VERSION ""

NS_ :

BS_:

BU_: Gateway EPS IBC RBU RWS PDCR

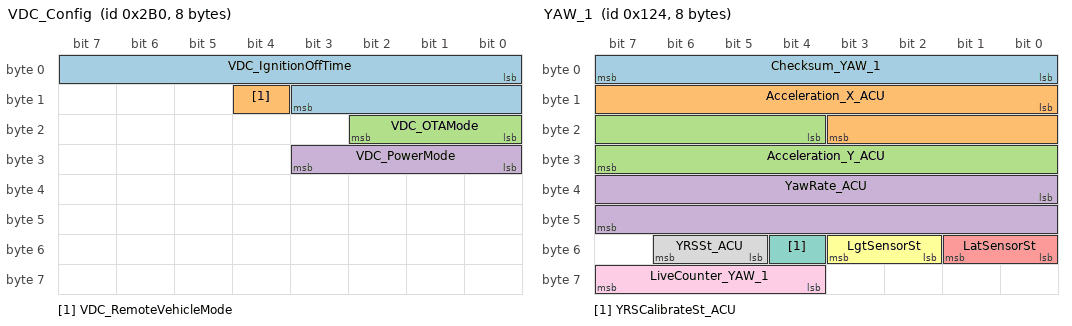
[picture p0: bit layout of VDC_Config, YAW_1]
BO_ 688 VDC_Config: 8 Gateway
 SG_ VDC_IgnitionOffTime : 0|12@1+ (1,0) [0|4095] "minute"  IBC
 SG_ VDC_RemoteVehicleMode : 12|1@1+ (1,0) [0|1] ""  EPS,IBC
 SG_ VDC_OTAMode : 16|3@1+ (1,0) [0|7] ""  EPS
 SG_ VDC_PowerMode : 24|4@1+ (1,0) [0|15] "" Vector__XXX

BO_ 292 YAW_1: 8 Gateway
 SG_ Checksum_YAW_1 : 0|8@1+ (1,0) [0|255] ""  EPS,IBC
 SG_ Acceleration_X_ACU : 8|12@1+ (0.001,-2) [-2|2] "g"  EPS,IBC
 SG_ Acceleration_Y_ACU : 20|12@1+ (0.001,-2) [-2|2] "g"  EPS,IBC
 SG_ YawRate_ACU : 32|16@1+ (0.01,-180) [-180|180] "deg/s"  EPS,IBC
 SG_ LatSensorSt : 48|2@1+ (1,0) [0|3] ""  EPS,IBC
 SG_ LgtSensorSt : 50|2@1+ (1,0) [0|3] ""  EPS,IBC
 SG_ YRSCalibrateSt_ACU : 52|1@1+ (1,0) [0|1] ""  EPS,IBC
 SG_ YRSSt_ACU : 53|2@1+ (1,0) [0|3] ""  EPS,IBC
 SG_ LiveCounter_YAW_1 : 60|4@1+ (1,0) [0|15] ""  EPS,IBC

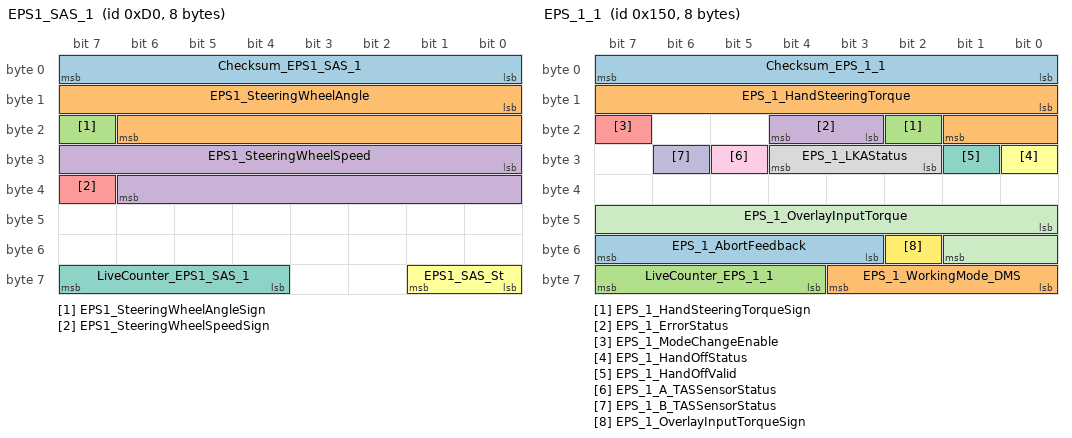
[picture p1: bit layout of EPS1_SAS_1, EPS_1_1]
BO_ 208 EPS1_SAS_1: 8 EPS
 SG_ Checksum_EPS1_SAS_1 : 0|8@1+ (1,0) [0|255] ""  Gateway
 SG_ EPS1_SteeringWheelAngle : 8|15@1+ (0.04375,0) [0|1433.55625] "°„"  Gateway
 SG_ EPS1_SteeringWheelAngleSign : 23|1@1+ (1,0) [0|1] ""  Gateway
 SG_ EPS1_SteeringWheelSpeed : 24|15@1+ (0.04375,0) [0|1433.55625] "°„/s"  Gateway
 SG_ EPS1_SteeringWheelSpeedSign : 39|1@1+ (1,0) [0|1] ""  Gateway
 SG_ EPS1_SAS_St : 56|2@1+ (1,0) [0|3] ""  Gateway
 SG_ LiveCounter_EPS1_SAS_1 : 60|4@1+ (1,0) [0|15] ""  Gateway

BO_ 336 EPS_1_1: 8 EPS
 SG_ Checksum_EPS_1_1 : 0|8@1+ (1,0) [0|255] ""  Gateway
 SG_ EPS_1_HandSteeringTorque : 8|10@1+ (0.01,0) [0|10] "Nm"  Gateway
 SG_ EPS_1_HandSteeringTorqueSign : 18|1@1+ (1,0) [0|1] ""  Gateway
 SG_ EPS_1_ErrorStatus : 19|2@1+ (1,0) [0|3] ""  Gateway
 SG_ EPS_1_ModeChangeEnable : 23|1@1+ (1,0) [0|1] ""  Gateway
 SG_ EPS_1_HandOffStatus : 24|1@1+ (1,0) [0|1] ""  Gateway
 SG_ EPS_1_HandOffValid : 25|1@1+ (1,0) [0|1] ""  Gateway
 SG_ EPS_1_LKAStatus : 26|3@1+ (1,0) [0|7] ""  Gateway
 SG_ EPS_1_A_TASSensorStatus : 29|1@1+ (1,0) [0|1] ""  Gateway
 SG_ EPS_1_B_TASSensorStatus : 30|1@1+ (1,0) [0|1] ""  Gateway
 SG_ EPS_1_OverlayInputTorque : 40|10@1+ (0.01,0) [0|10] "Nm"  Gateway
 SG_ EPS_1_OverlayInputTorqueSign : 50|1@1+ (1,0) [0|1] ""  Gateway
 SG_ EPS_1_AbortFeedback : 51|5@1+ (1,0) [0|31] ""  Gateway
 SG_ EPS_1_WorkingMode_DMS : 56|4@1+ (1,0) [0|15] ""  Gateway
 SG_ LiveCounter_EPS_1_1 : 60|4@1+ (1,0) [0|15] "Pulse"  Gateway

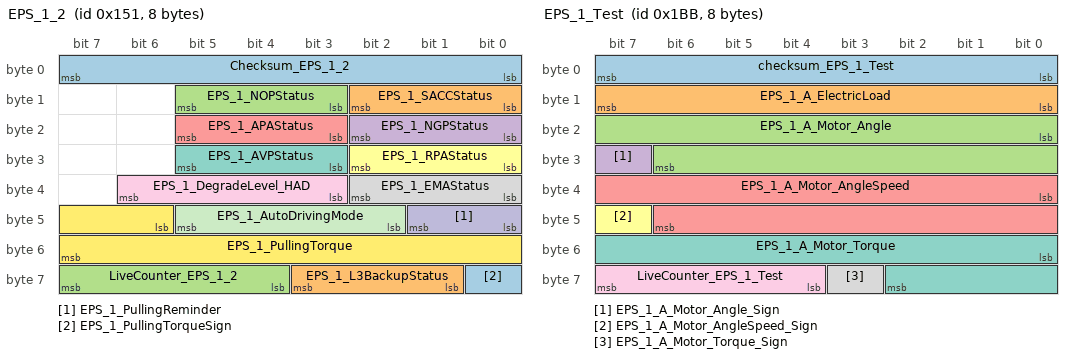
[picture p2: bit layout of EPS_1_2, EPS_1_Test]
BO_ 337 EPS_1_2: 8 EPS
 SG_ Checksum_EPS_1_2 : 0|8@1+ (1,0) [0|255] ""  Gateway
 SG_ EPS_1_SACCStatus : 8|3@1+ (1,0) [0|7] ""  Gateway
 SG_ EPS_1_NOPStatus : 11|3@1+ (1,0) [0|7] ""  Gateway
 SG_ EPS_1_NGPStatus : 16|3@1+ (1,0) [0|7] ""  Gateway
 SG_ EPS_1_APAStatus : 19|3@1+ (1,0) [0|7] ""  Gateway
 SG_ EPS_1_RPAStatus : 24|3@1+ (1,0) [0|7] ""  Gateway
 SG_ EPS_1_AVPStatus : 27|3@1+ (1,0) [0|7] ""  Gateway
 SG_ EPS_1_EMAStatus : 32|3@1+ (1,0) [0|7] ""  Gateway
 SG_ EPS_1_DegradeLevel_HAD : 35|4@1+ (1,0) [0|15] ""  Gateway
 SG_ EPS_1_PullingReminder : 40|2@1+ (1,0) [0|3] ""  Gateway
 SG_ EPS_1_AutoDrivingMode : 42|4@1+ (1,0) [0|15] ""  Gateway
 SG_ EPS_1_PullingTorque : 46|10@1+ (0.01,0) [0|10] "Nm"  Gateway
 SG_ EPS_1_PullingTorqueSign : 56|1@1+ (1,0) [0|1] ""  Gateway
 SG_ EPS_1_L3BackupStatus : 57|3@1+ (1,0) [0|7] ""  Gateway
 SG_ LiveCounter_EPS_1_2 : 60|4@1+ (1,0) [0|15] ""  Gateway

BO_ 443 EPS_1_Test: 8 EPS
 SG_ checksum_EPS_1_Test : 0|8@1+ (1,0) [0|255] ""  Gateway
 SG_ EPS_1_A_ElectricLoad : 8|8@1+ (0.5,0) [0|125] "A"  Gateway
 SG_ EPS_1_A_Motor_Angle : 16|15@1+ (0.04375,0) [0|1433.55625] "°„"  Gateway
 SG_ EPS_1_A_Motor_Angle_Sign : 31|1@1+ (1,0) [0|1] ""  Gateway
 SG_ EPS_1_A_Motor_AngleSpeed : 32|15@1+ (0.04375,0) [0|1433.55625] "rad/s"  Gateway
 SG_ EPS_1_A_Motor_AngleSpeed_Sign : 47|1@1+ (1,0) [0|1] ""  Gateway
 SG_ EPS_1_A_Motor_Torque : 48|11@1+ (0.01,0) [0|20] "Nm"  Gateway
 SG_ EPS_1_A_Motor_Torque_Sign : 59|1@1+ (1,0) [0|1] ""  Gateway
 SG_ LiveCounter_EPS_1_Test : 60|4@1+ (1,0) [0|15] "pulse"  Gateway

BO_ 1210 OTA_VersionEPS: 8 EPS
 SG_ SoftwareNumber_EPS : 0|24@1+ (1,0) [0|0] ""  Gateway
 SG_ HardwareRelated_ConfigID_EPS : 24|16@1+ (1,0) [0|0] ""  Gateway

BO_ 192 ABS_1: 32 IBC
 SG_ Checksum_ABS_1 : 0|8@1+ (1,0) [0|255] ""  Gateway
 SG_ WheelSpeed_FL : 8|15@1+ (0.01,0) [0|327.67] "km/h"  Gateway
 SG_ WheelSpeed_FR : 24|15@1+ (0.01,0) [0|327.67] "km/h"  Gateway
 SG_ WheelSpeed_RL : 40|15@1+ (0.01,0) [0|327.67] "km/h"  Gateway
 SG_ WheelSpeed_RR : 56|15@1+ (0.01,0) [0|327.67] "km/h"  Gateway
 SG_ WheelPulse_FL : 72|8@1+ (1,0) [0|255] ""  Gateway
 SG_ WheelPulse_FR : 80|8@1+ (1,0) [0|255] ""  Gateway
 SG_ WheelPulse_RL : 88|8@1+ (1,0) [0|255] ""  Gateway
 SG_ WheelPulse_RR : 96|8@1+ (1,0) [0|255] ""  Gateway
 SG_ WheelSpeedDirection_FL : 104|2@1+ (1,0) [0|3] ""  Gateway
 SG_ WheelSpeedDirection_FR : 106|2@1+ (1,0) [0|3] ""  Gateway
 SG_ WheelSpeedDirection_RL : 108|2@1+ (1,0) [0|3] ""  Gateway
 SG_ WheelSpeedDirection_RR : 110|2@1+ (1,0) [0|3] ""  Gateway
 SG_ WheelSpeedDirection_FL_Q : 112|1@1+ (1,0) [0|1] ""  Gateway
 SG_ WheelSpeedDirection_FR_Q : 113|1@1+ (1,0) [0|1] ""  Gateway
 SG_ WheelSpeedDirection_RL_Q : 114|1@1+ (1,0) [0|1] ""  Gateway
 SG_ WheelSpeedDirection_RR_Q : 115|1@1+ (1,0) [0|1] ""  Gateway
 SG_ VehicleSpeed : 120|15@1+ (0.01,0) [0|327.67] "km/h"  Gateway
 SG_ VehiclSpeed_Q : 135|1@1+ (1,0) [0|1] ""  Gateway
 SG_ DrivingDirection : 136|2@1+ (1,0) [0|3] ""  Gateway
 SG_ DrivingDirection_Q : 138|1@1+ (1,0) [0|1] ""  Gateway
 SG_ BrakeTorqueOnWheels : 152|12@1+ (2,0) [0|8190] "Nm"  Gateway
 SG_ EstimatedWheelPressure_FL : 168|14@1+ (0.03125,-50) [-50|450] "bar"  Gateway
 SG_ EstimatedWheelPressure_FR : 184|14@1+ (0.03125,-50) [-50|450] "bar"  Gateway
 SG_ EstimatedWheelPressure_RL : 200|14@1+ (0.03125,-50) [-50|450] "bar"  Gateway
 SG_ EstimatedWheelPressure_RR : 216|14@1+ (0.03125,-50) [-50|450] "bar"  Gateway
 SG_ LiveCounter_ABS_1 : 252|4@1+ (1,0) [0|15] ""  Gateway

BO_ 195 ESC_1_W: 32 IBC
 SG_ Checksum_ESC_1_W : 0|8@1+ (1,0) [0|255] ""  Gateway
 SG_ TorqueReductionFast_TCS_FrontWhe : 24|13@1+ (1,0) [0|8000] "Nm"  Gateway
 SG_ TorqueIncrease_MSR_FrontWheel : 40|14@1+ (1,-8000) [-8000|8000] "Nm"  Gateway
 SG_ TorqueReductionFast_TCS_RearWhee : 72|13@1+ (1,0) [0|8000] "Nm"  Gateway
 SG_ TorqueIncrease_MSR_RearWheel : 88|14@1+ (1,-8000) [-8000|8000] "Nm"  Gateway
 SG_ ESC_RegenerationTorqueRequest : 104|13@1+ (1,-8000) [-8000|0] "Nm"  Gateway
 SG_ ESC_RegenerationTorqueRequest_Q : 134|2@1+ (1,0) [0|3] ""  Gateway
 SG_ TorqReductionFastSt_TCS_FrontWhe : 138|1@1+ (1,0) [0|1] ""  Gateway
 SG_ TorqueIncreaseSt_MSR_FrontWheel : 140|1@1+ (1,0) [0|1] ""  Gateway
 SG_ TorqReductionFastSt_TCS_RearWhee : 146|1@1+ (1,0) [0|1] ""  Gateway
 SG_ TorqueIncreaseSt_MSR_RearWheel : 148|1@1+ (1,0) [0|1] ""  Gateway
 SG_ ESC_StatusRegenerationTorqueRequ : 150|1@1+ (1,0) [0|1] ""  Gateway
 SG_ ESC_FrontBiasMax : 152|7@1+ (1,0) [0|100] "%"  Gateway
 SG_ ESC_RearBiasMax : 160|7@1+ (1,0) [0|100] "%"  Gateway
 SG_ LiveCounter_ESC_1_W : 252|4@1+ (1,0) [0|15] ""  Gateway

BO_ 306 ESC_2_1: 24 IBC
 SG_ Checksum_ESC_2_1 : 0|8@1+ (1,0) [0|255] ""  Gateway
 SG_ WorkingSt_ESC : 8|1@1+ (1,0) [0|1] ""  Gateway
 SG_ ErrorSt_ESC : 9|1@1+ (1,0) [0|1] ""  Gateway
 SG_ Intervention_ESC : 10|1@1+ (1,0) [0|1] ""  Gateway
 SG_ ErrorSt_ABS : 11|1@1+ (1,0) [0|1] ""  Gateway
 SG_ Intervention_ABS : 12|1@1+ (1,0) [0|1] ""  Gateway
 SG_ ESC_Status_RollerBenchMode : 13|1@1+ (1,0) [0|1] ""  Gateway
 SG_ Intervention_TCS : 14|1@1+ (1,0) [0|1] ""  Gateway
 SG_ ErrorSt_EBD : 15|1@1+ (1,0) [0|1] ""  Gateway
 SG_ AvailableSt_CDP : 16|1@1+ (1,0) [0|1] ""  Gateway
 SG_ Intervention_CDP : 17|1@1+ (1,0) [0|1] ""  Gateway
 SG_ AvailableSt_HHC : 24|1@1+ (1,0) [0|1] ""  Gateway
 SG_ Intervention_HHC : 25|1@1+ (1,0) [0|1] ""  Gateway
 SG_ AvailableSt_HDC : 26|1@1+ (1,0) [0|1] ""  Gateway
 SG_ WorkingSt_HDC : 27|2@1+ (1,0) [0|3] ""  Gateway
 SG_ ErrorSt_AVH : 29|1@1+ (1,0) [0|1] ""  Gateway
 SG_ WorkingSt_AVH : 30|2@1+ (1,0) [0|3] ""  Gateway
 SG_ AvailableSt_AEB : 34|1@1+ (1,0) [0|1] ""  Gateway
 SG_ Intervention_AEB : 35|1@1+ (1,0) [0|1] ""  Gateway
 SG_ AvailableSt_ABP : 36|1@1+ (1,0) [0|1] ""  Gateway
 SG_ Intervention_ABP : 37|1@1+ (1,0) [0|1] ""  Gateway
 SG_ AvailableSt_AWB : 38|1@1+ (1,0) [0|1] ""  Gateway
 SG_ Intervention_AWB : 39|1@1+ (1,0) [0|1] ""  Gateway
 SG_ AvailableSt_HBA : 40|1@1+ (1,0) [0|1] ""  Gateway
 SG_ Intervention_HBA : 41|1@1+ (1,0) [0|1] ""  Gateway
 SG_ Intervention_EmergencyBrake : 45|1@1+ (1,0) [0|1] ""  Gateway
 SG_ VehicleStandstillSt_ESC : 46|1@1+ (1,0) [0|1] ""  Gateway
 SG_ BrakeLightCtrlCmd_ESC : 47|1@1+ (1,0) [0|1] ""  Gateway
 SG_ Intervention_BTCS_F : 50|1@1+ (1,0) [0|1] ""  Gateway
 SG_ Intervention_BTCS_R : 51|1@1+ (1,0) [0|1] ""  Gateway
 SG_ AvailableSt_MSR : 52|1@1+ (1,0) [0|1] ""  Gateway
 SG_ RoughRoadLevel : 57|3@1+ (1,0) [0|7] ""  Gateway
 SG_ BrakeHoldActive : 60|1@1+ (1,0) [0|1] ""  Gateway
 SG_ ParkingRequestToEPB : 62|2@1+ (1,0) [0|3] ""  Gateway
 SG_ WorkingMode_ESC : 64|4@1+ (1,0) [0|15] ""  Gateway
 SG_ ModeChangeEnable_ESC : 69|1@1+ (1,0) [0|1] ""  Gateway
 SG_ WorkingSt_CST : 72|2@1+ (1,0) [0|3] ""  Gateway
 SG_ LiveCounter_ESC_2_1 : 188|4@1+ (1,0) [0|15] ""  Gateway

BO_ 312 ESC_5_1: 24 IBC
 SG_ Checksum_ESC_5_1 : 0|8@1+ (1,0) [0|255] ""  Gateway
 SG_ ESC_TorqueReq_VMC_1 : 8|17@1+ (0.25,-13000) [-13000|13000] "Nm"  Gateway
 SG_ ESC_TorqueReqSt_VMC_1 : 28|2@1+ (1,0) [0|3] ""  Gateway
 SG_ ESC_TargetGearReq_VMC_1 : 32|3@1+ (1,0) [0|7] ""  Gateway
 SG_ ESC_TargetGearReqEnable_VMC_1 : 35|1@1+ (1,0) [0|1] ""  Gateway
 SG_ ESC_SuspendStatus_L2 : 36|3@1+ (1,0) [0|7] ""  Gateway
 SG_ ESC_EPBAvailableSt_L3 : 39|1@1+ (1,0) [0|1] ""  Gateway
 SG_ ESC_CommunicationSt_L3 : 40|1@1+ (1,0) [0|1] ""  Gateway
 SG_ ESC_UsedChannel_L3 : 41|2@1+ (1,0) [0|3] ""  Gateway
 SG_ ESC_ControllerReleaseSt_L3 : 43|1@1+ (1,0) [0|1] ""  Gateway
 SG_ ESC_SuspendStatusByDriver_L3 : 44|2@1+ (1,0) [0|3] ""  Gateway
 SG_ ESC_SuspendStatusByOther_L3 : 46|1@1+ (1,0) [0|1] ""  Gateway
 SG_ ESC_VLC_Error_L12 : 50|2@1+ (1,0) [0|3] ""  Gateway
 SG_ ESC_VLCSt : 52|2@1+ (1,0) [0|3] ""  Gateway
 SG_ ESC_VMC_Error_L3 : 54|3@1+ (1,0) [0|7] ""  Gateway
 SG_ ESC_AutoDriving_LC_Brakemode : 57|2@1+ (1,0) [0|3] ""  Gateway
 SG_ ESC_AutoPark_LC_HPA_Avail : 59|2@1+ (1,0) [0|3] ""  Gateway
 SG_ ESC_AutoPark_LCSt : 72|3@1+ (1,0) [0|7] ""  Gateway
 SG_ ESC_AutoPark_LC_APA_Avail : 76|2@1+ (1,0) [0|3] ""  Gateway
 SG_ ESC_AutoPark_LC_RPA_Avail : 80|2@1+ (1,0) [0|3] ""  Gateway
 SG_ ESC_AutoPark_LC_AVP_Avail : 84|2@1+ (1,0) [0|3] ""  Gateway
 SG_ ESC_AutoPark_LCFailureSt : 88|4@1+ (1,0) [0|15] ""  Gateway
 SG_ ESC_AutoPark_LC_BrakeMode : 92|2@1+ (1,0) [0|3] ""  Gateway
 SG_ ESC_HDCActiveForbidden : 104|1@1+ (1,0) [0|1] ""  Gateway
 SG_ ESC_ESCOffForbidden : 105|1@1+ (1,0) [0|1] ""  Gateway
 SG_ ESC_AVHActiveForbidden : 106|1@1+ (1,0) [0|1] ""  Gateway
 SG_ ESC_ShutOffFinished : 107|1@1+ (1,0) [0|1] ""  Gateway
 SG_ ESC_BrakePadelOverride : 108|1@1+ (1,0) [0|1] ""  Gateway
 SG_ LiveCounter_ESC_5_1 : 188|4@1+ (1,0) [0|15] "Pulse"  Gateway

BO_ 193 IBC_1: 32 IBC
 SG_ Checksum_IBC_1 : 0|8@1+ (1,0) [0|255] ""  Gateway
 SG_ IBC_SimulatorPressure : 8|10@1+ (0.3,-5) [-5|301.9] "bar"  Gateway
 SG_ IBC_SimulatorPressureSt : 18|1@1+ (1,0) [0|1] ""  Gateway
 SG_ IBC_SystemStatus : 19|3@1+ (1,0) [0|7] ""  Gateway
 SG_ IBC_PlungerPressure : 24|10@1+ (0.3,-5) [-5|301.9] "bar"  Gateway
 SG_ IBC_PlungerPressureSt : 34|1@1+ (1,0) [0|1] ""  Gateway
 SG_ IBC_BrakePedalStatus_Q : 38|2@1+ (1,0) [0|3] ""  Gateway
 SG_ IBC_InputRodStroke : 40|10@1+ (0.05,-5) [-5|46.15] "mm"  Gateway
 SG_ IBC_InputRodStrokeSt : 50|1@1+ (1,0) [0|1] ""  Gateway
 SG_ IBC_BrakeFluidWarning : 51|2@1+ (1,0) [0|3] ""  Gateway
 SG_ IBC_BrakePedalStatus : 53|2@1+ (1,0) [0|3] ""  Gateway
 SG_ TwoFootBrakeSt : 57|1@1+ (1,0) [0|1] ""  Gateway
 SG_ DegradedBBFWarning : 58|1@1+ (1,0) [0|1] ""  Gateway
 SG_ IBC_MILInfo : 59|1@1+ (1,0) [0|1] ""  Gateway
 SG_ FWAWarning : 60|2@1+ (1,0) [0|3] ""  Gateway
 SG_ IBC_RearWheelAngleRequest : 64|12@1+ (0.01,-20.48) [-20.48|20.47] "°„"  Gateway
 SG_ IBC_RearWheelAngleRequestSt : 76|1@1+ (1,0) [0|1] ""  Gateway
 SG_ IBC_VDCActive : 77|1@1+ (1,0) [0|1] ""  Gateway
 SG_ LiveCounter_IBC_1 : 252|4@1+ (1,0) [0|15] ""  Gateway

BO_ 513 IBC_Data: 8 IBC
 SG_ IBCdata : 0|64@1+ (1,0) [0|0] ""  Gateway

BO_ 1381 IBC_SlaveFVReq: 8 IBC
 SG_ SECOC_FVReqCode_IBC : 0|8@1+ (1,0) [0|0] ""  Gateway

BO_ 1260 OTA_VersionIBC: 8 IBC
 SG_ SoftwareNumber_IBC : 0|24@1+ (1,0) [0|0] ""  Gateway
 SG_ HardwareRelated_ConfigID_IBC : 24|16@1+ (1,0) [0|0] ""  Gateway

BO_ 1199 OTA_VersionRBU: 8 RBU
 SG_ SoftwareNumber_RBU : 0|24@1+ (1,0) [0|0] ""  Gateway
 SG_ HardwareRelated_ConfigID_RBU : 24|16@1+ (1,0) [0|0] ""  Gateway

BO_ 169 RBU_1: 32 RBU
 SG_ Checksum_RBU_1 : 0|8@1+ (1,0) [0|255] ""  Gateway
 SG_ RBU_WheelSpeed_FL : 8|15@1+ (0.01,0) [0|327.67] "km/h"  Gateway
 SG_ RBU_WheelSpeed_FR : 24|15@1+ (0.01,0) [0|327.67] "km/h"  Gateway
 SG_ RBU_WheelSpeed_RL : 40|15@1+ (0.01,0) [0|327.67] "km/h"  Gateway
 SG_ RBU_WheelSpeed_RR : 56|15@1+ (0.01,0) [0|327.67] "km/h"  Gateway
 SG_ RBU_ErrorSt_SBS : 72|1@1+ (1,0) [0|1] ""  Gateway
 SG_ RBU_Intervention_SBS : 73|1@1+ (1,0) [0|1] ""  Gateway
 SG_ RBU_EPBAvailableSt_L3 : 74|1@1+ (1,0) [0|1] ""  Gateway
 SG_ RBU_UsedChannel_L3 : 75|2@1+ (1,0) [0|3] ""  Gateway
 SG_ RBU_ControllerReleaseSt_L3 : 77|1@1+ (1,0) [0|1] ""  Gateway
 SG_ RBU_SuspendStatusByDriver_L3 : 78|2@1+ (1,0) [0|3] ""  Gateway
 SG_ RBU_BrakePedalStatus_Q : 80|2@1+ (1,0) [0|3] ""  Gateway
 SG_ RBU_BrakePedalStatus : 82|2@1+ (1,0) [0|3] ""  Gateway
 SG_ RBU_VLCSt : 84|2@1+ (1,0) [0|3] ""  Gateway
 SG_ RBU_VMC_Error_L3 : 88|3@1+ (1,0) [0|7] ""  Gateway
 SG_ RBU_DrivingDirection : 91|2@1+ (1,0) [0|3] ""  Gateway
 SG_ RBU_VehicleSpeed : 96|15@1+ (0.01,0) [0|327.67] "km/h"  Gateway
 SG_ RBU_TargetGearReq_VMC_1 : 114|3@1+ (1,0) [0|7] ""  Gateway
 SG_ RBU_TargetGearReqEnable_VMC_1 : 117|1@1+ (1,0) [0|1] ""  Gateway
 SG_ RBU_VehicleStandstillSt : 118|1@1+ (1,0) [0|1] ""  Gateway
 SG_ RBU_BrakeLightCtrlCmd : 119|1@1+ (1,0) [0|1] ""  Gateway
 SG_ LiveCounter_RBU_1 : 252|4@1+ (1,0) [0|15] ""  Gateway

BO_ 1382 RBU_SlaveFVReq: 8 RBU
 SG_ SECOC_FVReqCode_RBU : 0|8@1+ (1,0) [0|0] ""  Gateway

BO_ 1214 OTA_VersionRWS: 8 RWS
 SG_ SoftwareNumber_RWS : 0|24@1+ (1,0) [0|0] ""  Gateway
 SG_ HardwareRelated_ConfigID_RWS : 24|16@1+ (1,0) [0|0] ""  Gateway

BO_ 188 RWS_1: 16 RWS
 SG_ Checksum_RWS_1 : 0|8@1+ (1,0) [0|255] ""  Gateway
 SG_ RearWheelAngle : 8|12@1+ (0.01,-20.48) [-20.48|20.47] "°„"  Gateway
 SG_ RearWheelAngle_QF : 22|2@1+ (1,0) [0|3] ""  Gateway
 SG_ RearWheelAngleSpeed : 24|13@1+ (0.01,-40.96) [-40.96|40.95] "°„/s"  Gateway
 SG_ WorkingSt_RWS : 40|3@1+ (1,0) [0|7] ""  Gateway
 SG_ ErrorSt_RWS : 43|2@1+ (1,0) [0|3] ""  Gateway
 SG_ LiveCounter_RWS_1 : 60|4@1+ (1,0) [0|15] ""  Gateway
 SG_ SECOC_FV_RWS_1 : 64|16@1+ (1,0) [0|0] ""  Gateway
 SG_ SECOC_TMAC_RWS_1 : 80|48@1+ (1,0) [0|0] ""  Gateway

BO_ 189 RWS_2: 8 RWS
 SG_ MaxAngle_RWS : 8|12@1+ (0.01,-20.48) [-20.48|20.47] "°„"  Gateway
 SG_ MaxAngleGrad_RWS : 24|13@1+ (0.01,-40.96) [-40.96|40.95] "°„/s"  Gateway

BO_ 1383 RWS_SlaveFVReq: 8 RWS
 SG_ SECOC_FVReqCode_RWS : 0|8@1+ (1,0) [0|0] ""  Gateway

BO_ 222 EPBSlaveReqToM: 8 PDCR
 SG_ PbcOutActuatorState_S : 8|3@1+ (1,0) [0|7] ""  Gateway
 SG_ PbcOutPadAdjustmentRequest_S : 12|1@1+ (1,0) [0|1] ""  Gateway
 SG_ PbcInHostAvailability_S : 13|2@1+ (1,0) [0|3] ""  Gateway
 SG_ PbcInApplyReleaseRequest_S : 16|4@1+ (1,0) [0|15] ""  Gateway
 SG_ PbcInRollerbenchActive_S : 20|1@1+ (1,0) [0|1] ""  Gateway
 SG_ PbcInDriveAwayIntentionIndi_0000 : 21|1@1+ (1,0) [0|1] ""  Gateway
 SG_ PbcEnableLineLock_S : 22|1@1+ (1,0) [0|1] ""  Gateway
 SG_ PbcEnableLineRelease_S : 23|1@1+ (1,0) [0|1] ""  Gateway
 SG_ EpbDegradedMode_S : 24|3@1+ (1,0) [0|7] ""  Gateway
 SG_ PbcDynApplyControlState_S : 28|4@1+ (1,0) [0|15] ""  Gateway
 SG_ PbcRollerbenchApplyControlS_0000 : 32|4@1+ (1,0) [0|15] ""  Gateway
 SG_ IsRelTchPt_S : 37|1@1+ (1,0) [0|1] ""  Gateway
 SG_ IsRWAAppEn_S : 38|1@1+ (1,0) [0|1] ""  Gateway
 SG_ IsRWARelEn_S : 39|1@1+ (1,0) [0|1] ""  Gateway
 SG_ RWACntrStpApp_S : 40|8@1+ (1,0) [0|255] "pulse"  Gateway
 SG_ CntrRWAAppHld_S : 48|8@1+ (1,0) [0|255] "pulse"  Gateway
 SG_ PbcRWAControlState_S : 56|4@1+ (1,0) [0|15] ""  Gateway

CM_ SG_ 688 VDC_IgnitionOffTime "Indicates the time between last IG off and this IG on. If the counter is overflow, it still sends 4093. The counter will be reset when IG Off";
CM_ SG_ 688 VDC_RemoteVehicleMode "The signal indicates the vehicle is in remote  mode or not";
CM_ SG_ 688 VDC_OTAMode "The signal indicates the vehicle is in OTA  mode or not";
CM_ SG_ 688 VDC_PowerMode "The signal indicates the vehicle power mode provided from VDC power mode module.";
CM_ SG_ 292 Checksum_YAW_1 "The checksum is used to check whether the data from the CPU buffer are shifted without transmission errors to the CAN communication controller buffer and vice versa.ChecksumFactor=0.";
CM_ SG_ 292 Acceleration_X_ACU "The signal is LongitudinalAcceleration(Raw value,with filtering,without compensated).Positive value represents  forward,  negative value represents backward. ";
CM_ SG_ 292 Acceleration_Y_ACU "The signal is Lateral Acceleration(Raw value,with filtering,without compensated).Positive value represents left side of vehicle, negative value represents  right side of vehicle. ";
CM_ SG_ 292 YawRate_ACU "This signal indicates the yaw rate raw data (RAW data,with filtering,without compensated; sign depends on mounting position)
anticlockwise=positive, clockwise=negative";
CM_ SG_ 292 LatSensorSt "The signal indicates Indicates Lateral Sensor State.";
CM_ SG_ 292 LgtSensorSt "The signal indicates indicates Longitudinal Sensor State";
CM_ SG_ 292 YRSCalibrateSt_ACU "This signal indicates YawRate Sensor Calibration State";
CM_ SG_ 292 YRSSt_ACU "The signal iIndicates YawRate Sensor State";
CM_ SG_ 292 LiveCounter_YAW_1 "The Livecounter is used to check the signal consistency of the messages . If the signals are consecutive, the LiveCounter should also be sequential in the way 0, 1, 2 °≠X(depends on E2E usage), 0, 1 °≠";
CM_ SG_ 208 Checksum_EPS1_SAS_1 "The checksum is used to check whether the data from the CPU buffer are shifted without transmission errors to the CAN communication controller buffer and vice versa.";
CM_ SG_ 208 EPS1_SteeringWheelAngle "This signal indicates the angle of steering wheel .";
CM_ SG_ 208 EPS1_SteeringWheelAngleSign "This signal shows the direction of steering wheel angle, it's used in pairs with °∞SteeringWheelAngle°±.";
CM_ SG_ 208 EPS1_SteeringWheelSpeed "This signal indicates the teering wheel rotation speed.";
CM_ SG_ 208 EPS1_SteeringWheelSpeedSign "This signal shows the direction of steering wheel speed, it's used in pairs with °∞SteeringWheelSpeed°±. ";
CM_ SG_ 208 EPS1_SAS_St "The signal indicates the status of SAS. ";
CM_ SG_ 208 LiveCounter_EPS1_SAS_1 "The Livecounter is used to check the signal consistency of the messages . If the signals are consecutive, the LiveCounter should also be sequential in the way 0, 1, 2 ...X(depends on E2E usage), 0, 1 °≠";
CM_ SG_ 336 EPS_1_HandSteeringTorque "The signal indicates the torque measured by the torque sensor at the steering wheel. In case of a sensor error, the default value (0x3FF) of the signal is set";
CM_ SG_ 336 EPS_1_HandSteeringTorqueSign "Indicates sign of hand steering torque (+/-)
Hand steering torque to left = positive
Hand steering torque to right = negative
";
CM_ SG_ 336 EPS_1_ErrorStatus "Error indication of the EPS system";
CM_ SG_ 336 EPS_1_ModeChangeEnable "Indicates whether EPS can change the working mode in the current condition";
CM_ SG_ 336 EPS_1_HandOffStatus "Detect if the driver is controlling the steering wheel";
CM_ SG_ 336 EPS_1_HandOffValid "Indicates if the hand off signal is valid or not.";
CM_ SG_ 336 EPS_1_LKAStatus "The signal indicates the status of LKA function ";
CM_ SG_ 336 EPS_1_A_TASSensorStatus "The signal indicates the status of torque sensor.";
CM_ SG_ 336 EPS_1_B_TASSensorStatus "The signal indicates the status of torque sensor.";
CM_ SG_ 336 EPS_1_OverlayInputTorque "The signal indicates the actual applied overlay toque in EPS.";
CM_ SG_ 336 EPS_1_OverlayInputTorqueSign "Indicates sign of OverlayInputTorque (+/-)
Hand steering torque to left = positive
Hand steering torque to right = negative
";
CM_ SG_ 336 EPS_1_AbortFeedback "EPS APA/L2/L3 Abort Feedback";
CM_ SG_ 336 EPS_1_WorkingMode_DMS "Indicates the current working mode of EPS as the feedback to the  command of Drive Mode Selection ECU";
CM_ SG_ 337 Checksum_EPS_1_2 "The checksum is used to check whether the data from the CPU buffer are shifted without transmission errors to the CAN communication controller buffer and vice versa.";
CM_ SG_ 337 EPS_1_SACCStatus "The signal indicates the status of SACC/LCA/HWA/TJA function ";
CM_ SG_ 337 EPS_1_NOPStatus "The signal indicates the status of NOP function ";
CM_ SG_ 337 EPS_1_NGPStatus "The signal indicates the status of NGP function ";
CM_ SG_ 337 EPS_1_APAStatus "The signal indicates the status of APA function ";
CM_ SG_ 337 EPS_1_RPAStatus "The signal indicates the status of RPA function ";
CM_ SG_ 337 EPS_1_AVPStatus "The signal indicates the status of AVP function ";
CM_ SG_ 337 EPS_1_EMAStatus "The signal indicates the status of EMA function ";
CM_ SG_ 337 EPS_1_DegradeLevel_HAD "EPS capability description under different faults for autonomous Driving";
CM_ SG_ 337 EPS_1_PullingReminder "Indicates the EPS pulling status.";
CM_ SG_ 337 EPS_1_AutoDrivingMode "Which auto driving/parking mode is active";
CM_ SG_ 337 EPS_1_PullingTorque "The signal indicates the Pulling torque in EPS.";
CM_ SG_ 337 EPS_1_PullingTorqueSign "Indicates sign of PullingTorque (+/-)
PullingTorque to left = positive
PullingTorque to right = negative
";
CM_ SG_ 337 EPS_1_L3BackupStatus "The signal indicates the status of L3Backup function";
CM_ SG_ 337 LiveCounter_EPS_1_2 "The Livecounter is used to check the signal consistency of the messages . If the signals are consecutive, the LiveCounter should also be sequential in the way 0, 1, 2 ...X(depends on E2E usage), 0, 1 °≠";
CM_ SG_ 443 EPS_1_A_Motor_Angle_Sign "left-positive; right-negative";
CM_ SG_ 443 EPS_1_A_Motor_AngleSpeed_Sign "left-positive; right-negative";
CM_ SG_ 443 EPS_1_A_Motor_Torque_Sign "left-positive; right-negative";
CM_ SG_ 1210 SoftwareNumber_EPS "TThis signal indicates the software number. The signal shll be proceeded following the requirement of OTS spec.";
CM_ SG_ 1210 HardwareRelated_ConfigID_EPS "This signal indicates the hardware related information about config ID.The signal shll be proceeded following the requirement of OTS spec.";
CM_ SG_ 192 Checksum_ABS_1 "The checksum is used to check whether the data from the CPU buffer are shifted without transmission errors to the CAN communication controller buffer and vice versa.";
CM_ SG_ 192 WheelSpeed_FL "This signal is front left wheel speed which sent by ABS with filtering. ";
CM_ SG_ 192 WheelSpeed_FR "This signal is front right wheel speed which sent by ABS with filtering.";
CM_ SG_ 192 WheelSpeed_RL "This signal is rear left wheel speed which sent by ABS with filtering.";
CM_ SG_ 192 WheelSpeed_RR "This signal is rear right wheel speed which sent by ABS with filtering.";
CM_ SG_ 192 WheelPulse_FL "This signal is the front left wheel speed pulse(raw data,without filtering,without compensated).";
CM_ SG_ 192 WheelPulse_FR "This signal is the front right wheel speed pulse(raw data,without filtering,without compensated).";
CM_ SG_ 192 WheelPulse_RL "This signal is the rear left wheel speed pulse(raw data,without filtering,without compensated).";
CM_ SG_ 192 WheelPulse_RR "This signal is the rear right wheel speed pulse(raw data,without filtering,without compensated).";
CM_ SG_ 192 WheelSpeedDirection_FL "This signal is the the front left wheel speed direction.";
CM_ SG_ 192 WheelSpeedDirection_FR "This signal is the the front right wheel speed direction.";
CM_ SG_ 192 WheelSpeedDirection_RL "This signal is the the rear left wheel speed direction.";
CM_ SG_ 192 WheelSpeedDirection_RR "This signal is the the rear right  wheel speed direction.";
CM_ SG_ 192 WheelSpeedDirection_FL_Q "Qualifier for WheelSpeedDirection_FL.";
CM_ SG_ 192 WheelSpeedDirection_FR_Q "Qualifier for WheelSpeedDirection_FR.";
CM_ SG_ 192 WheelSpeedDirection_RL_Q "Qualifier for WheelSpeedDirection_RL.";
CM_ SG_ 192 WheelSpeedDirection_RR_Q "Qualifier for WheelSpeedDirection_RR.";
CM_ SG_ 192 VehicleSpeed "The signal describes the raw vehicle speed calculated by ABS. The ABS calculates the vehicle speed based on the raw wheel speed signals from the wheel speed sensors. The vehicle speed output could be the average of the wheel speeds of the driven axle.";
CM_ SG_ 192 VehiclSpeed_Q "Qualifier for VehicleSpeed";
CM_ SG_ 192 DrivingDirection "The signal indicates driving direction of the vehicle.";
CM_ SG_ 192 DrivingDirection_Q "Qualifier for DrivingDirection";
CM_ SG_ 192 BrakeTorqueOnWheels "This signal is the total hydraulic bake torque on 4 wheels(Except EPB etc.).If current brake torque is over 8188Nm,it will always send the max value 8188 Nm.";
CM_ SG_ 192 EstimatedWheelPressure_FL "The signal indicates the estimated or modeled wheel pressure of the respective wheel brake of front left.";
CM_ SG_ 192 EstimatedWheelPressure_FR "The signal indicates the estimated or modeled wheel pressure of the respective wheel brake of front right.";
CM_ SG_ 192 EstimatedWheelPressure_RL "The signal indicates the estimated or modeled wheel pressure of the respective wheel brake of rear left.";
CM_ SG_ 192 EstimatedWheelPressure_RR "The signal indicates the estimated or modeled wheel pressure of the respective wheel brake of rear left.";
CM_ SG_ 192 LiveCounter_ABS_1 "The Livecounter is used to check the signal consistency of the messages . If the signals are consecutive, the LiveCounter should also be sequential in the way 0, 1, 2 ...X(depends on E2E usage), 0, 1 °≠";
CM_ SG_ 195 Checksum_ESC_1_W "The checksum is used to check whether the data from the CPU buffer are shifted without transmission errors to the CAN communication controller buffer and vice versa.";
CM_ SG_ 195 TorqueReductionFast_TCS_FrontWhe "The signal describes a fast torque reduction request (inner torque level) from TCS, realized by air reduction via throttle position adjustment. The request for fast torque reduction is sent in the driving torque control mode (AMR). In case of no torque request: TorqueReductionFast_TCS = 0x1FFE. In case of an error, the error value 0x1FFF is sent.,the torque is  wheel torque.";
CM_ SG_ 195 TorqueIncrease_MSR_FrontWheel "The signal describes the torque increase request (inner torque level) from MSR. In case of no torque request: TorqueIncrease_MSR = 0x3FFE. In case of an error, the error value 0x3FFF is sent,the torque is  wheel torque.";
CM_ SG_ 195 TorqueReductionFast_TCS_RearWhee "The signal describes a fast torque reduction request (inner torque level) from TCS, realized by air reduction via throttle position adjustment. The request for fast torque reduction is sent in the driving torque control mode (AMR). In case of no torque request: TorqueReductionFast_TCS = 0x1FFE. In case of an error, the error value 0x1FFF is sent.,the torque is  wheel torque.";
CM_ SG_ 195 TorqueIncrease_MSR_RearWheel "The signal describes the torque increase request (inner torque level) from MSR. In case of no torque request: TorqueIncrease_MSR = 0x3FFE. In case of an error, the error value 0x3FFF is sent,the torque is  wheel torque.";
CM_ SG_ 195 ESC_RegenerationTorqueRequest "RegenerationTorqueRequest,the torque is  wheel torque.
Recovery torque, HCU to be treated as negative";
CM_ SG_ 195 ESC_RegenerationTorqueRequest_Q "The quality of signal ESC_RegenerationTorqueRequest";
CM_ SG_ 195 TorqReductionFastSt_TCS_FrontWhe "This signal indicates the status of torque fast reduction request from TCS.";
CM_ SG_ 195 TorqueIncreaseSt_MSR_FrontWheel "This signal indicates the status of troque increase request from MSR.";
CM_ SG_ 195 TorqReductionFastSt_TCS_RearWhee "This signal indicates the status of torque fast reduction request from TCS.";
CM_ SG_ 195 TorqueIncreaseSt_MSR_RearWheel "This signal indicates the status of troque increase request from MSR.";
CM_ SG_ 195 ESC_StatusRegenerationTorqueRequ "status of regneration torque request";
CM_ SG_ 195 ESC_FrontBiasMax "The maximum bias of front axle for brake regeneration.";
CM_ SG_ 195 ESC_RearBiasMax "The maximum bias of rear axle for brake regeneration.";
CM_ SG_ 195 LiveCounter_ESC_1_W "The Livecounter is used to check the signal consistency of the messages . If the signals are consecutive, the LiveCounter should also be sequential in the way 0, 1, 2 ...X(depends on E2E usage), 0, 1 °≠";
CM_ SG_ 306 Checksum_ESC_2_1 "The checksum is used to check whether the data from the CPU buffer are shifted without transmission errors to the CAN communication controller buffer and vice versa.";
CM_ SG_ 306 WorkingSt_ESC "This signal indicates the ESC system working status.";
CM_ SG_ 306 ErrorSt_ESC "This signal indicates the ESC function error status,including VDC and TCS.";
CM_ SG_ 306 Intervention_ESC "The signal is indicates if the ESC function is intervention or not.";
CM_ SG_ 306 ErrorSt_ABS "This signal indicates the ABS function error status.";
CM_ SG_ 306 Intervention_ABS "The signal indicates if the ABS function is intervention or not.";
CM_ SG_ 306 ESC_Status_RollerBenchMode "The signal indicates the status of roller bench mode.";
CM_ SG_ 306 Intervention_TCS "The signal indicates if the TCS function is intervention or not.";
CM_ SG_ 306 ErrorSt_EBD "This signal indicates the EBD function error status.";
CM_ SG_ 306 AvailableSt_CDP "This signal Indicates if the CDP function is available or not";
CM_ SG_ 306 Intervention_CDP "The signal is indicates if the CDP function is intervention or not.";
CM_ SG_ 306 AvailableSt_HHC "This signal indicates if the HHC function is available or not";
CM_ SG_ 306 Intervention_HHC "The signal is indicates if the HHC function is intervention or not.";
CM_ SG_ 306 AvailableSt_HDC "This signal indicates if the HDC function is available or not";
CM_ SG_ 306 WorkingSt_HDC "The signal indicates the working status of HDC.";
CM_ SG_ 306 ErrorSt_AVH "This signal indicates if the AVH function is error or not";
CM_ SG_ 306 WorkingSt_AVH "The signal indicates the woking status of AVH.
When AVH is standby , it means AVH is On, but not active braking.
When AVH is active , it means AVH is On and active braking.
When AVH is inactive, it  means AVH already on but not ready intervention";
CM_ SG_ 306 AvailableSt_AEB "This signal indicates the AEB function is available or not.";
CM_ SG_ 306 Intervention_AEB "The signal is indicates if the AEB function is intervention or not.";
CM_ SG_ 306 AvailableSt_ABP "This signal indicates the ABP function is available or not.";
CM_ SG_ 306 Intervention_ABP "The signal is indicates if the  ABP function is intervention or not.";
CM_ SG_ 306 AvailableSt_AWB "This signal indicates if the AWB function is available or not";
CM_ SG_ 306 Intervention_AWB "The signal is indicates if the AWB function is intervention or not.";
CM_ SG_ 306 AvailableSt_HBA "This signal indicates if the HBA is available or not";
CM_ SG_ 306 Intervention_HBA "This signal Indicates if the HBA is intervention or not.";
CM_ SG_ 306 Intervention_EmergencyBrake "The signal is indicates if the EmergencyBrake is Intervention or not.
This signal is used to light the flash when the speed is over 50kph and  brake deceleration over 0.6G or ABS is intervention";
CM_ SG_ 306 VehicleStandstillSt_ESC "The signal indicates the vehicle whether is in standstill or not.";
CM_ SG_ 306 BrakeLightCtrlCmd_ESC "The signal indicates the brake light control command.";
CM_ SG_ 306 Intervention_BTCS_F "The signal indicates if the BTCS of front axle is intervention or not.";
CM_ SG_ 306 Intervention_BTCS_R "The signal indicates if the BTCS of rear axle is intervention or not.";
CM_ SG_ 306 AvailableSt_MSR "This signal indicates if the MSR function is available or not";
CM_ SG_ 306 RoughRoadLevel "This signal Indicates the level of rough road. Inactive is defined as the vehicle is stop. Level 6 is defined as the most serious Rough level";
CM_ SG_ 306 BrakeHoldActive "This signal is used to EPB to judge that it is currently holding pressure. If holding pressure fails, EPB needs to actively clamp";
CM_ SG_ 306 ParkingRequestToEPB " indicates the release/lock brake request to EPB ";
CM_ SG_ 306 WorkingMode_ESC "This signal indicates the current working mode of ESC as the feedback to the  command of Drive Mode Selection ECU.";
CM_ SG_ 306 ModeChangeEnable_ESC "This signal indicates if the working mode of ESC can be changed or not.
";
CM_ SG_ 306 WorkingSt_CST "The signal indicates the woking status of CST.
When CST is Off, it means CST is disabled/init/default.
When CST is Standby , it means CST is On, but not active braking.
When CST is Intervention , it means CST is On and active braking.
When CST is Error, it  means CST is in error status.";
CM_ SG_ 306 LiveCounter_ESC_2_1 "The Livecounter is used to check the signal consistency of the messages . If the signals are consecutive, the LiveCounter should also be sequential in the way 0, 1, 2 ...X(depends on E2E usage), 0, 1 °≠";
CM_ SG_ 312 Checksum_ESC_5_1 "The checksum is used to check whether the data from the CPU buffer are shifted without transmission errors to the CAN communication controller buffer and vice versa.";
CM_ SG_ 312 ESC_TorqueReq_VMC_1 "This signal indicates the target torque request (wheel side vehcle level)";
CM_ SG_ 312 ESC_TorqueReqSt_VMC_1 "This signal indicates the status of signal ESC_TorqueReq_VMC.";
CM_ SG_ 312 ESC_TargetGearReq_VMC_1 "ESC request to change the lever  position.";
CM_ SG_ 312 ESC_TargetGearReqEnable_VMC_1 "This signal is enable flag for gear request of ADAS Control";
CM_ SG_ 312 ESC_SuspendStatus_L2 "This signal indicates if the VMC system is suspend during L2 Function";
CM_ SG_ 312 ESC_EPBAvailableSt_L3 "This signal indicates EPB communication is available or not";
CM_ SG_ 312 ESC_CommunicationSt_L3 "This signal indicates L3 relevant network communication can be received or not.";
CM_ SG_ 312 ESC_UsedChannel_L3 "This signal indicates ESC feedback which communication channel is used for L3 control.";
CM_ SG_ 312 ESC_ControllerReleaseSt_L3 "This signal indicates ESC is available for L3 autodriving function or not.Release means IBC is available for L3 Control£¨Notrelease means IBC is not available for L3 Control.";
CM_ SG_ 312 ESC_SuspendStatusByDriver_L3 "This signal indicates if the VMC system is suspend during L3 Function(Driver)";
CM_ SG_ 312 ESC_SuspendStatusByOther_L3 "This signal indicates if the VMC system is suspend during L3 Function(Other)";
CM_ SG_ 312 ESC_VLC_Error_L12 "This signal indicates ESC is available for L12 autodriving function or not.";
CM_ SG_ 312 ESC_VLCSt "This signal indicates the vehicle longitudinal control status for L123 autodriving function.";
CM_ SG_ 312 ESC_VMC_Error_L3 "This signal indicates VMC system in ESC is available for L3 autodriving function or not.";
CM_ SG_ 312 ESC_AutoDriving_LC_Brakemode "This signal indicates Longitudinal controller brake mode
Only used in L3 function";
CM_ SG_ 312 ESC_AutoPark_LC_HPA_Avail "This signal indicates if theHPA function available or not ";
CM_ SG_ 312 ESC_AutoPark_LCSt "This signal indicates the longitudinal controller status";
CM_ SG_ 312 ESC_AutoPark_LC_APA_Avail "This signal indicates if the APA function available or not ";
CM_ SG_ 312 ESC_AutoPark_LC_RPA_Avail "This signal indicates if the RPA function available or not ";
CM_ SG_ 312 ESC_AutoPark_LC_AVP_Avail "This signal indicates if the AVP function available or not ";
CM_ SG_ 312 ESC_AutoPark_LCFailureSt "This signal indicates  the failure of the longitudinal controller";
CM_ SG_ 312 ESC_AutoPark_LC_BrakeMode "This signal indicates Longitudinal controller brake mode";
CM_ SG_ 312 ESC_HDCActiveForbidden "The signal indicates that ESC forbidden user active HDC on some condition such as auto pilot.";
CM_ SG_ 312 ESC_ESCOffForbidden "The signal indicates that ESC forbidden user turn off ESC on some condition such as auto pilot.";
CM_ SG_ 312 ESC_AVHActiveForbidden "The signal indicates that ESC forbidden user active AVH on some condition such as auto pilot.";
CM_ SG_ 312 ESC_ShutOffFinished "Indicates  that the shut off of VMC is finished.";
CM_ SG_ 312 ESC_BrakePadelOverride "This signal indicates driver brakes more than the system during AutoParking function. ";
CM_ SG_ 312 LiveCounter_ESC_5_1 "The Livecounter is used to check the signal consistency of the messages . If the signals are consecutive, the LiveCounter should also be sequential in the way 0, 1, 2 ...X(depends on E2E usage), 0, 1 °≠";
CM_ SG_ 193 Checksum_IBC_1 "The checksum is used to check whether the data from the CPU buffer are shifted without transmission errors to the CAN communication controller buffer and vice versa.";
CM_ SG_ 193 IBC_SimulatorPressure "The signal indicates the simulator Master cylinder pressure.";
CM_ SG_ 193 IBC_SimulatorPressureSt "The signal indicates the simulator pressure is valid or not.";
CM_ SG_ 193 IBC_SystemStatus "This signal indicates the status of IBC system.";
CM_ SG_ 193 IBC_PlungerPressure "The signal indicates the plunger pressure.";
CM_ SG_ 193 IBC_PlungerPressureSt "The signal indicates the plunger pressure is valid or not.";
CM_ SG_ 193 IBC_BrakePedalStatus_Q "This signal is the qualifier of brake pedal status.";
CM_ SG_ 193 IBC_InputRodStroke "The signal indicates the brake pedal stroke.";
CM_ SG_ 193 IBC_InputRodStrokeSt "The signal indicates  the brake pedal stroke is valid or not.";
CM_ SG_ 193 IBC_BrakeFluidWarning "This signal is the liquid level sensor signal on the oil pot.";
CM_ SG_ 193 IBC_BrakePedalStatus "This signal is the brake pedal status.";
CM_ SG_ 193 TwoFootBrakeSt "The signal indicates the driver pressed the brake pedal and the accelerator pedal at the same time";
CM_ SG_ 193 DegradedBBFWarning "This signal indicates degraded BBF(Brake Boost Function) warning";
CM_ SG_ 193 IBC_MILInfo "The MIL light is activated by IBC if the emission related errors are detected. This signal shall be reserved and fixed to 0x0 if there is no OBD requirement, e.g. EV vehicle.";
CM_ SG_ 193 FWAWarning "This signal indicates brake system over temperature warning.";
CM_ SG_ 193 IBC_RearWheelAngleRequest "Target RWS angle from VDC2.0
anticlockwise=positive, clockwise=negative";
CM_ SG_ 193 IBC_RearWheelAngleRequestSt "The signal indicates the Rear wheel angle request is valid or not.";
CM_ SG_ 193 IBC_VDCActive "The signal indicates the Vehicle instability is valid or not.";
CM_ SG_ 193 LiveCounter_IBC_1 "The Livecounter is used to check the signal consistency of the messages . If the signals are consecutive, the LiveCounter should also be sequential in the way 0, 1, 2 ...X(depends on E2E usage), 0, 1 °≠";
CM_ SG_ 513 IBCdata "Reserved for IBC testing.";
CM_ SG_ 1381 SECOC_FVReqCode_IBC "FV  request code. The signal shall be procceded following the byte order requirement in FAW-CYS-0033, i.e. SECOC spec";
CM_ SG_ 1260 SoftwareNumber_IBC "TThis signal indicates the software number. The signal shll be proceeded following the requirement of OTS spec.";
CM_ SG_ 1260 HardwareRelated_ConfigID_IBC "This signal indicates the hardware related information about config ID.The signal shll be proceeded following the requirement of OTS spec.";
CM_ SG_ 1199 SoftwareNumber_RBU "TThis signal indicates the software number. The signal shll be proceeded following the requirement of OTS spec.";
CM_ SG_ 1199 HardwareRelated_ConfigID_RBU "This signal indicates the hardware related information about config ID.The signal shll be proceeded following the requirement of OTS spec.";
CM_ SG_ 169 Checksum_RBU_1 "The checksum is used to check whether the data from the CPU buffer are shifted without transmission errors to the CAN communication controller buffer and vice versa.";
CM_ SG_ 169 RBU_WheelSpeed_FL "This signal is front left wheel speed which sent by ABS with filtering. ";
CM_ SG_ 169 RBU_WheelSpeed_FR "This signal is front right wheel speed which sent by ABS with filtering.";
CM_ SG_ 169 RBU_WheelSpeed_RL "This signal is rear left wheel speed which sent by ABS with filtering.";
CM_ SG_ 169 RBU_WheelSpeed_RR "This signal is rear right wheel speed which sent by ABS with filtering.";
CM_ SG_ 169 RBU_ErrorSt_SBS "This signal indicates the SBS function error status.";
CM_ SG_ 169 RBU_Intervention_SBS "The signal indicates if the SBS function is intervention or not.";
CM_ SG_ 169 RBU_EPBAvailableSt_L3 "This signal indicates EPB communication is available or not by RBU";
CM_ SG_ 169 RBU_UsedChannel_L3 "This signal indicates RBU feedback which communication channel is used for L3 control.";
CM_ SG_ 169 RBU_ControllerReleaseSt_L3 "This signal indicates RBU is available for L3 autodriving function or not.Release means RBU is available for L3 Control£¨Notrelease means RBU is not available for L3 Control.";
CM_ SG_ 169 RBU_SuspendStatusByDriver_L3 "This signal indicates if the RBU system is suspend during L3 Function(Driver)";
CM_ SG_ 169 RBU_BrakePedalStatus_Q "This signal is the qualifier of brake pedal status.";
CM_ SG_ 169 RBU_BrakePedalStatus "This signal is the brake pedal status.";
CM_ SG_ 169 RBU_VLCSt "This signal indicates the vehicle longitudinal control status for L123 autodriving function.";
CM_ SG_ 169 RBU_VMC_Error_L3 "This signal indicates RBU system in RBU is available for L3 autodriving function or not.";
CM_ SG_ 169 RBU_DrivingDirection "The signal indicates driving direction of the vehicle.";
CM_ SG_ 169 RBU_VehicleSpeed "The signal describes the raw vehicle speed calculated by ABS. The ABS calculates the vehicle speed based on the raw wheel speed signals from the wheel speed sensors. The vehicle speed output could be the average of the wheel speeds of the driven axle.";
CM_ SG_ 169 RBU_TargetGearReq_VMC_1 "RBU request to change the lever  position.";
CM_ SG_ 169 RBU_TargetGearReqEnable_VMC_1 "This signal is enable flag for gear request of ADAS Control by RBU";
CM_ SG_ 169 RBU_VehicleStandstillSt "The signal indicates the vehicle whether is in standstill or not by RBU";
CM_ SG_ 169 RBU_BrakeLightCtrlCmd "The signal indicates the brake light control command of RBU";
CM_ SG_ 169 LiveCounter_RBU_1 "The Livecounter is used to check the signal consistency of the messages . If the signals are consecutive, the LiveCounter should also be sequential in the way 0, 1, 2 ...X(depends on E2E usage), 0, 1 °≠";
CM_ SG_ 1382 SECOC_FVReqCode_RBU "FV  request code. The signal shall be procceded following the byte order requirement in FAW-CYS-0033, i.e. SECOC spec";
CM_ SG_ 1214 SoftwareNumber_RWS "TThis signal indicates the software number. The signal shll be proceeded following the requirement of OTS spec.";
CM_ SG_ 1214 HardwareRelated_ConfigID_RWS "This signal indicates the hardware related information about config ID.The signal shll be proceeded following the requirement of OTS spec.";
CM_ SG_ 188 Checksum_RWS_1 "The checksum is used to check whether the data from the CPU buffer are shifted without transmission errors to the CAN communication controller buffer and vice versa.";
CM_ SG_ 188 RearWheelAngle "This signal indicates the angle of rear wheel
anticlockwise=positive, clockwise=negative";
CM_ SG_ 188 RearWheelAngle_QF "This signal indicates the quality factor of rear wheel angle:
0x0 stands for inaccurate data (Invalid)
0x1 stands for temporary undefined data (initial)
0x2 stands for data accuracy not within specification (inaccurate)
0x3 stands for undefined data accuracy (Valid)";
CM_ SG_ 188 RearWheelAngleSpeed "This signal indicates the angle speed of rear wheel";
CM_ SG_ 188 WorkingSt_RWS "This signal indicates the working state of RWS:
0x0 stands for Initialisation
0x1 stands for Pending
0x2 stands for Normal
0x3 stands for Red
0x4 stands for Yellow
0x5 stands for Ramping
0x6 stands for Inactive
0x7 stands for Diagnosis";
CM_ SG_ 188 ErrorSt_RWS "This signal indicates the system error status of RWS:
0x0 stands for system no error reports
0x1 stands for Error_Yellow
0x2 stands for Error_Red
0x3 is reserved";
CM_ SG_ 188 LiveCounter_RWS_1 "The Livecounter is used to check the signal consistency of the messages . If the signals are consecutive, the LiveCounter should also be sequential in the way 0, 1, 2 °≠X(depends on E2E usage), 0, 1 °≠";
CM_ SG_ 188 SECOC_FV_RWS_1 "Fresh value signal for SECOC. The signal shall be proceeded following the byte order requirement in FAW-CYS-0033, i.e. SECOC spec";
CM_ SG_ 188 SECOC_TMAC_RWS_1 "Truncated MAC signal for SECOC. The signal shall be proceeded following the byte order requirement in FAW-CYS-0033, i.e. SECOC spec";
CM_ SG_ 189 MaxAngle_RWS "Function safety allowed max. steer angle depends on vehicle speed from RWS actuator
anticlockwise=positive, clockwise=negative";
CM_ SG_ 189 MaxAngleGrad_RWS "This signal indicates the angle speed of rear wheel";
CM_ SG_ 1383 SECOC_FVReqCode_RWS "FV  request code. The signal shall be procceded following the byte order requirement in FAW-CYS-0033, i.e. SECOC spec";
CM_ SG_ 222 PbcOutActuatorState_S "The signal indicates the PBC out actuator  status of EPB slave.";
CM_ SG_ 222 PbcOutPadAdjustmentRequest_S "The signal indicates the PBC out pad adjustment request of EPB slave.";
CM_ SG_ 222 PbcInHostAvailability_S "The signal indicates the PBC in host availability of EPB slave.";
CM_ SG_ 222 PbcInApplyReleaseRequest_S "The signal indicates the PBC in request of EPB slave.";
CM_ SG_ 222 PbcInRollerbenchActive_S "The signal indicates the brake light control command of EPB slave.";
CM_ SG_ 222 PbcInDriveAwayIntentionIndi_0000 "The signal indicates the PBC in drive-away intention indication of EPB slave.";
CM_ SG_ 222 PbcEnableLineLock_S "The signal indicates the PBC enable line lock status of EPB slave of EPB slave.";
CM_ SG_ 222 PbcEnableLineRelease_S "The signal indicates the PBC enable line release status of EPB slave of EPB slave.";
CM_ SG_ 222 EpbDegradedMode_S "The signal indicates the degrade status of EPB slave.";
CM_ SG_ 222 PbcDynApplyControlState_S "The signal indicates the PBC dynamic apply control state of EPB slave.";
CM_ SG_ 222 PbcRollerbenchApplyControlS_0000 "The signal indicates the PBC roller-bench apply control state of EPB slave.
";
CM_ SG_ 222 IsRelTchPt_S "The signal indicates the brake pad diviation status of  EPB slave.";
CM_ SG_ 222 IsRWAAppEn_S "The signal indicates the RWA apply enable status of  EPB slave.";
CM_ SG_ 222 IsRWARelEn_S "The signal indicates the RWA release enable status of  EPB slave.";
CM_ SG_ 222 RWACntrStpApp_S "The signal indicates the RWA stp apply counter.";
CM_ SG_ 222 CntrRWAAppHld_S "The signal indicates the RWU App hold counter.";
CM_ SG_ 222 PbcRWAControlState_S "The signal indicates the PBC RWA control state of EPB slave.
";
BA_DEF_ BO_  "VFrameFormat" ENUM  "StandardCAN","ExtendedCAN","reserved","reserved","reserved","reserved","reserved","reserved","reserved","reserved","reserved","reserved","reserved","reserved","StandardCAN_FD","ExtendedCAN_FD";
BA_DEF_ BO_  "GenMsgILSupport" ENUM  "No","Yes";
BA_DEF_ BO_  "CanTpSTmin" INT 0 0;
BA_DEF_ BO_  "CanTpFcFrameId" HEX 0 2147483647;
BA_DEF_ BO_  "GenMsgSendType" ENUM  "Cyclic","not_used","not_used","not_used","not_used","Cyclic","not_used","IfActive","NoMsgSendType","Spontaneous","CyclicAndSpontaneous","NoMsgSendType";
BA_DEF_ BO_  "GenMsgCycleTime" INT 0 0;
BA_DEF_ SG_  "GenSigSendType" ENUM  "Cyclic","OnWrite","OnWriteWithRepetition","OnChange","OnChangeWithRepetition","IfActive","IfActiveWithRepetition","NoSigSendType";
BA_DEF_ SG_  "GenSigStartValue" INT 0 0;
BA_DEF_ SG_  "GenSigInvalidValue" INT 0 0;
BA_DEF_ SG_  "GenSigStartRemark" STRING ;
BA_DEF_ SG_  "GenSigInvalidRemark" STRING ;
BA_DEF_ SG_  "GenSigEvent" STRING ;
BA_DEF_ SG_  "SystemSignalLongSymbol" STRING ;
BA_DEF_REL_ BU_SG_REL_  "GenSigTimeoutTime" INT 0 5000;
BA_DEF_DEF_  "VFrameFormat" "ExtendedCAN_FD";
BA_DEF_DEF_  "GenMsgILSupport" "Yes";
BA_DEF_DEF_  "CanTpSTmin" 1;
BA_DEF_DEF_  "CanTpFcFrameId" 2147483647;
BA_DEF_DEF_REL_ "GenSigTimeoutTime" 0;
BA_DEF_DEF_  "GenMsgSendType" "Cyclic";
BA_DEF_DEF_  "GenMsgCycleTime" 0;
BA_DEF_DEF_  "GenSigSendType" "NoSigSendType";
BA_DEF_DEF_  "GenSigStartValue" 0;
BA_DEF_DEF_  "GenSigInvalidValue" 0;
BA_DEF_DEF_  "GenSigStartRemark" "";
BA_DEF_DEF_  "GenSigInvalidRemark" "";
BA_DEF_DEF_  "GenSigEvent" "";
BA_DEF_DEF_  "SystemSignalLongSymbol" "";
BA_ "GenMsgCycleTime" BO_ 688 100;
BA_ "VFrameFormat" BO_ 688 14;
BA_ "GenMsgCycleTime" BO_ 292 10;
BA_ "VFrameFormat" BO_ 292 14;
BA_ "GenMsgCycleTime" BO_ 208 10;
BA_ "VFrameFormat" BO_ 208 14;
BA_ "GenMsgCycleTime" BO_ 336 20;
BA_ "VFrameFormat" BO_ 336 14;
BA_ "GenMsgCycleTime" BO_ 337 20;
BA_ "VFrameFormat" BO_ 337 14;
BA_ "GenMsgCycleTime" BO_ 443 20;
BA_ "VFrameFormat" BO_ 443 14;
BA_ "GenMsgCycleTime" BO_ 1210 5000;
BA_ "VFrameFormat" BO_ 1210 14;
BA_ "GenMsgCycleTime" BO_ 192 10;
BA_ "VFrameFormat" BO_ 192 14;
BA_ "GenMsgCycleTime" BO_ 195 10;
BA_ "VFrameFormat" BO_ 195 14;
BA_ "GenMsgCycleTime" BO_ 306 10;
BA_ "VFrameFormat" BO_ 306 14;
BA_ "GenMsgCycleTime" BO_ 312 20;
BA_ "VFrameFormat" BO_ 312 14;
BA_ "GenMsgCycleTime" BO_ 193 10;
BA_ "VFrameFormat" BO_ 193 14;
BA_ "GenMsgCycleTime" BO_ 513 100;
BA_ "VFrameFormat" BO_ 513 14;
BA_ "GenMsgCycleTime" BO_ 1381 50;
BA_ "VFrameFormat" BO_ 1381 14;
BA_ "GenMsgCycleTime" BO_ 1260 5000;
BA_ "VFrameFormat" BO_ 1260 14;
BA_ "GenMsgCycleTime" BO_ 1199 5000;
BA_ "VFrameFormat" BO_ 1199 14;
BA_ "GenMsgCycleTime" BO_ 169 10;
BA_ "VFrameFormat" BO_ 169 14;
BA_ "GenMsgCycleTime" BO_ 1382 50;
BA_ "VFrameFormat" BO_ 1382 14;
BA_ "GenMsgCycleTime" BO_ 1214 5000;
BA_ "VFrameFormat" BO_ 1214 14;
BA_ "GenMsgCycleTime" BO_ 188 10;
BA_ "VFrameFormat" BO_ 188 14;
BA_ "GenMsgCycleTime" BO_ 189 10;
BA_ "VFrameFormat" BO_ 189 14;
BA_ "GenMsgCycleTime" BO_ 1383 50;
BA_ "VFrameFormat" BO_ 1383 14;
BA_ "GenMsgCycleTime" BO_ 222 10;
BA_ "VFrameFormat" BO_ 222 14;
BA_ "GenSigInvalidRemark" SG_ 688 VDC_IgnitionOffTime "O";
BA_ "GenSigStartRemark" SG_ 688 VDC_IgnitionOffTime "O";
BA_ "GenSigInvalidValue" SG_ 688 VDC_IgnitionOffTime 4095;
BA_ "GenSigStartValue" SG_ 688 VDC_IgnitionOffTime 4094;
BA_ "GenSigInvalidValue" SG_ 688 VDC_PowerMode 15;
BA_ "GenSigStartRemark" SG_ 292 Checksum_YAW_1 "V";
BA_ "GenSigInvalidValue" SG_ 292 Acceleration_X_ACU 4095;
BA_ "GenSigStartValue" SG_ 292 Acceleration_X_ACU 2000;
BA_ "GenSigInvalidValue" SG_ 292 Acceleration_Y_ACU 4095;
BA_ "GenSigStartValue" SG_ 292 Acceleration_Y_ACU 2000;
BA_ "GenSigInvalidValue" SG_ 292 YawRate_ACU 65535;
BA_ "GenSigStartValue" SG_ 292 YawRate_ACU 18000;
BA_ "GenSigStartRemark" SG_ 208 Checksum_EPS1_SAS_1 "V";
BA_ "GenSigInvalidRemark" SG_ 208 EPS1_SteeringWheelAngle "O";
BA_ "GenSigInvalidValue" SG_ 208 EPS1_SteeringWheelAngle 32767;
BA_ "GenSigInvalidRemark" SG_ 208 EPS1_SteeringWheelSpeed "O";
BA_ "GenSigInvalidValue" SG_ 208 EPS1_SteeringWheelSpeed 32767;
BA_ "GenSigStartValue" SG_ 208 EPS1_SAS_St 1;
BA_ "GenSigStartRemark" SG_ 336 Checksum_EPS_1_1 "V";
BA_ "GenSigInvalidValue" SG_ 336 EPS_1_HandSteeringTorque 1023;
BA_ "GenSigStartValue" SG_ 336 EPS_1_HandSteeringTorque 1022;
BA_ "GenSigInvalidValue" SG_ 336 EPS_1_OverlayInputTorque 1023;
BA_ "GenSigStartValue" SG_ 336 EPS_1_OverlayInputTorque 1022;
BA_ "GenSigInvalidValue" SG_ 336 EPS_1_WorkingMode_DMS 15;
BA_ "GenSigStartRemark" SG_ 337 Checksum_EPS_1_2 "V";
BA_ "GenSigInvalidValue" SG_ 337 EPS_1_PullingTorque 1023;
BA_ "GenSigStartValue" SG_ 337 EPS_1_PullingTorque 1022;
BA_ "GenSigStartRemark" SG_ 443 checksum_EPS_1_Test "V";
BA_ "GenSigInvalidValue" SG_ 443 EPS_1_A_ElectricLoad 255;
BA_ "GenSigStartValue" SG_ 443 EPS_1_A_ElectricLoad 254;
BA_ "GenSigInvalidRemark" SG_ 443 EPS_1_A_Motor_Angle "O";
BA_ "GenSigInvalidValue" SG_ 443 EPS_1_A_Motor_Angle 32767;
BA_ "GenSigInvalidRemark" SG_ 443 EPS_1_A_Motor_AngleSpeed "O";
BA_ "GenSigInvalidValue" SG_ 443 EPS_1_A_Motor_AngleSpeed 32767;
BA_ "GenSigStartRemark" SG_ 192 Checksum_ABS_1 "V";
BA_ "GenSigInvalidRemark" SG_ 192 WheelSpeed_FL "O";
BA_ "GenSigStartRemark" SG_ 192 WheelSpeed_FL "O";
BA_ "GenSigInvalidValue" SG_ 192 WheelSpeed_FL 32767;
BA_ "GenSigStartValue" SG_ 192 WheelSpeed_FL 32766;
BA_ "GenSigInvalidRemark" SG_ 192 WheelSpeed_FR "O";
BA_ "GenSigStartRemark" SG_ 192 WheelSpeed_FR "O";
BA_ "GenSigInvalidValue" SG_ 192 WheelSpeed_FR 32767;
BA_ "GenSigStartValue" SG_ 192 WheelSpeed_FR 32766;
BA_ "GenSigInvalidRemark" SG_ 192 WheelSpeed_RL "O";
BA_ "GenSigStartRemark" SG_ 192 WheelSpeed_RL "O";
BA_ "GenSigInvalidValue" SG_ 192 WheelSpeed_RL 32767;
BA_ "GenSigStartValue" SG_ 192 WheelSpeed_RL 32766;
BA_ "GenSigInvalidRemark" SG_ 192 WheelSpeed_RR "O";
BA_ "GenSigStartRemark" SG_ 192 WheelSpeed_RR "O";
BA_ "GenSigInvalidValue" SG_ 192 WheelSpeed_RR 32767;
BA_ "GenSigStartValue" SG_ 192 WheelSpeed_RR 32766;
BA_ "GenSigInvalidRemark" SG_ 192 WheelPulse_FL "O";
BA_ "GenSigStartRemark" SG_ 192 WheelPulse_FL "O";
BA_ "GenSigInvalidValue" SG_ 192 WheelPulse_FL 255;
BA_ "GenSigStartValue" SG_ 192 WheelPulse_FL 254;
BA_ "GenSigInvalidRemark" SG_ 192 WheelPulse_FR "O";
BA_ "GenSigStartRemark" SG_ 192 WheelPulse_FR "O";
BA_ "GenSigInvalidValue" SG_ 192 WheelPulse_FR 255;
BA_ "GenSigStartValue" SG_ 192 WheelPulse_FR 254;
BA_ "GenSigInvalidRemark" SG_ 192 WheelPulse_RL "O";
BA_ "GenSigStartRemark" SG_ 192 WheelPulse_RL "O";
BA_ "GenSigInvalidValue" SG_ 192 WheelPulse_RL 255;
BA_ "GenSigStartValue" SG_ 192 WheelPulse_RL 254;
BA_ "GenSigInvalidRemark" SG_ 192 WheelPulse_RR "O";
BA_ "GenSigStartRemark" SG_ 192 WheelPulse_RR "O";
BA_ "GenSigInvalidValue" SG_ 192 WheelPulse_RR 255;
BA_ "GenSigStartValue" SG_ 192 WheelPulse_RR 254;
BA_ "GenSigInvalidRemark" SG_ 192 VehicleSpeed "O";
BA_ "GenSigStartRemark" SG_ 192 VehicleSpeed "O";
BA_ "GenSigInvalidValue" SG_ 192 VehicleSpeed 32767;
BA_ "GenSigStartValue" SG_ 192 VehicleSpeed 32766;
BA_ "GenSigInvalidRemark" SG_ 192 BrakeTorqueOnWheels "O";
BA_ "GenSigInvalidValue" SG_ 192 BrakeTorqueOnWheels 4095;
BA_ "GenSigInvalidValue" SG_ 192 EstimatedWheelPressure_FL 16383;
BA_ "GenSigStartValue" SG_ 192 EstimatedWheelPressure_FL 16382;
BA_ "GenSigInvalidValue" SG_ 192 EstimatedWheelPressure_FR 16383;
BA_ "GenSigStartValue" SG_ 192 EstimatedWheelPressure_FR 16382;
BA_ "GenSigInvalidValue" SG_ 192 EstimatedWheelPressure_RL 16383;
BA_ "GenSigStartValue" SG_ 192 EstimatedWheelPressure_RL 16382;
BA_ "GenSigInvalidValue" SG_ 192 EstimatedWheelPressure_RR 16383;
BA_ "GenSigStartValue" SG_ 192 EstimatedWheelPressure_RR 16382;
BA_ "GenSigStartRemark" SG_ 195 Checksum_ESC_1_W "V";
BA_ "GenSigInvalidValue" SG_ 195 TorqueReductionFast_TCS_FrontWhe 8191;
BA_ "GenSigStartValue" SG_ 195 TorqueReductionFast_TCS_FrontWhe 8190;
BA_ "SystemSignalLongSymbol" SG_ 195 TorqueReductionFast_TCS_FrontWhe "TorqueReductionFast_TCS_FrontWheel";
BA_ "GenSigInvalidValue" SG_ 195 TorqueIncrease_MSR_FrontWheel 16383;
BA_ "GenSigStartValue" SG_ 195 TorqueIncrease_MSR_FrontWheel 16382;
BA_ "GenSigInvalidValue" SG_ 195 TorqueReductionFast_TCS_RearWhee 8191;
BA_ "GenSigStartValue" SG_ 195 TorqueReductionFast_TCS_RearWhee 8190;
BA_ "SystemSignalLongSymbol" SG_ 195 TorqueReductionFast_TCS_RearWhee "TorqueReductionFast_TCS_RearWheel";
BA_ "GenSigInvalidValue" SG_ 195 TorqueIncrease_MSR_RearWheel 16383;
BA_ "GenSigStartValue" SG_ 195 TorqueIncrease_MSR_RearWheel 16382;
BA_ "GenSigInvalidValue" SG_ 195 ESC_RegenerationTorqueRequest 8191;
BA_ "GenSigStartValue" SG_ 195 ESC_RegenerationTorqueRequest 8190;
BA_ "SystemSignalLongSymbol" SG_ 195 TorqReductionFastSt_TCS_FrontWhe "TorqReductionFastSt_TCS_FrontWheel";
BA_ "SystemSignalLongSymbol" SG_ 195 TorqReductionFastSt_TCS_RearWhee "TorqReductionFastSt_TCS_RearWheel";
BA_ "SystemSignalLongSymbol" SG_ 195 ESC_StatusRegenerationTorqueRequ "ESC_StatusRegenerationTorqueRequest";
BA_ "GenSigInvalidValue" SG_ 195 ESC_FrontBiasMax 127;
BA_ "GenSigStartValue" SG_ 195 ESC_FrontBiasMax 126;
BA_ "GenSigInvalidValue" SG_ 195 ESC_RearBiasMax 127;
BA_ "GenSigStartValue" SG_ 195 ESC_RearBiasMax 126;
BA_ "GenSigStartRemark" SG_ 306 Checksum_ESC_2_1 "V";
BA_ "GenSigStartValue" SG_ 306 WorkingSt_ESC 1;
BA_ "GenSigStartValue" SG_ 306 AvailableSt_HBA 1;
BA_ "GenSigInvalidValue" SG_ 306 RoughRoadLevel 7;
BA_ "GenSigInvalidValue" SG_ 306 WorkingMode_ESC 15;
BA_ "GenSigStartRemark" SG_ 312 Checksum_ESC_5_1 "V";
BA_ "GenSigInvalidValue" SG_ 312 ESC_TorqueReq_VMC_1 131071;
BA_ "GenSigStartValue" SG_ 312 ESC_TorqueReq_VMC_1 131070;
BA_ "GenSigInvalidValue" SG_ 312 ESC_VMC_Error_L3 7;
BA_ "GenSigInvalidValue" SG_ 312 ESC_AutoPark_LCSt 7;
BA_ "GenSigInvalidValue" SG_ 312 ESC_AutoPark_LCFailureSt 15;
BA_ "GenSigStartRemark" SG_ 193 Checksum_IBC_1 "V";
BA_ "GenSigInvalidRemark" SG_ 193 IBC_SimulatorPressure "O";
BA_ "GenSigStartRemark" SG_ 193 IBC_SimulatorPressure "O";
BA_ "GenSigInvalidValue" SG_ 193 IBC_SimulatorPressure 1023;
BA_ "GenSigStartValue" SG_ 193 IBC_SimulatorPressure 1022;
BA_ "GenSigInvalidRemark" SG_ 193 IBC_PlungerPressure "O";
BA_ "GenSigStartRemark" SG_ 193 IBC_PlungerPressure "O";
BA_ "GenSigInvalidValue" SG_ 193 IBC_PlungerPressure 1023;
BA_ "GenSigStartValue" SG_ 193 IBC_PlungerPressure 1022;
BA_ "GenSigInvalidRemark" SG_ 193 IBC_InputRodStroke "O";
BA_ "GenSigStartRemark" SG_ 193 IBC_InputRodStroke "O";
BA_ "GenSigInvalidValue" SG_ 193 IBC_InputRodStroke 1023;
BA_ "GenSigStartValue" SG_ 193 IBC_InputRodStroke 1022;
BA_ "GenSigInvalidValue" SG_ 193 IBC_BrakeFluidWarning 3;
BA_ "GenSigInvalidValue" SG_ 193 IBC_BrakePedalStatus 3;
BA_ "GenSigInvalidValue" SG_ 193 IBC_RearWheelAngleRequest 4095;
BA_ "GenSigStartValue" SG_ 193 IBC_RearWheelAngleRequest 4094;
BA_ "GenSigStartRemark" SG_ 169 Checksum_RBU_1 "V";
BA_ "GenSigInvalidRemark" SG_ 169 RBU_WheelSpeed_FL "O";
BA_ "GenSigStartRemark" SG_ 169 RBU_WheelSpeed_FL "O";
BA_ "GenSigInvalidValue" SG_ 169 RBU_WheelSpeed_FL 32767;
BA_ "GenSigStartValue" SG_ 169 RBU_WheelSpeed_FL 32766;
BA_ "GenSigInvalidRemark" SG_ 169 RBU_WheelSpeed_FR "O";
BA_ "GenSigStartRemark" SG_ 169 RBU_WheelSpeed_FR "O";
BA_ "GenSigInvalidValue" SG_ 169 RBU_WheelSpeed_FR 32767;
BA_ "GenSigStartValue" SG_ 169 RBU_WheelSpeed_FR 32766;
BA_ "GenSigInvalidRemark" SG_ 169 RBU_WheelSpeed_RL "O";
BA_ "GenSigStartRemark" SG_ 169 RBU_WheelSpeed_RL "O";
BA_ "GenSigInvalidValue" SG_ 169 RBU_WheelSpeed_RL 32767;
BA_ "GenSigStartValue" SG_ 169 RBU_WheelSpeed_RL 32766;
BA_ "GenSigInvalidRemark" SG_ 169 RBU_WheelSpeed_RR "O";
BA_ "GenSigStartRemark" SG_ 169 RBU_WheelSpeed_RR "O";
BA_ "GenSigInvalidValue" SG_ 169 RBU_WheelSpeed_RR 32767;
BA_ "GenSigStartValue" SG_ 169 RBU_WheelSpeed_RR 32766;
BA_ "GenSigInvalidValue" SG_ 169 RBU_BrakePedalStatus 3;
BA_ "GenSigInvalidValue" SG_ 169 RBU_VMC_Error_L3 7;
BA_ "GenSigInvalidValue" SG_ 169 RBU_DrivingDirection 3;
BA_ "GenSigInvalidRemark" SG_ 169 RBU_VehicleSpeed "O";
BA_ "GenSigStartRemark" SG_ 169 RBU_VehicleSpeed "O";
BA_ "GenSigInvalidValue" SG_ 169 RBU_VehicleSpeed 32767;
BA_ "GenSigStartValue" SG_ 169 RBU_VehicleSpeed 32766;
BA_ "GenSigStartRemark" SG_ 188 Checksum_RWS_1 "V";
BA_ "SystemSignalLongSymbol" SG_ 222 PbcInDriveAwayIntentionIndi_0000 "PbcInDriveAwayIntentionIndication_S";
BA_ "SystemSignalLongSymbol" SG_ 222 PbcRollerbenchApplyControlS_0000 "PbcRollerbenchApplyControlState_S";
BA_REL_ "GenSigTimeoutTime" BU_SG_REL_ IBC SG_ 688 VDC_IgnitionOffTime 1000;
BA_REL_ "GenSigTimeoutTime" BU_SG_REL_ EPS SG_ 688 VDC_RemoteVehicleMode 1000;
BA_REL_ "GenSigTimeoutTime" BU_SG_REL_ IBC SG_ 688 VDC_RemoteVehicleMode 1000;
BA_REL_ "GenSigTimeoutTime" BU_SG_REL_ EPS SG_ 688 VDC_OTAMode 1000;
BA_REL_ "GenSigTimeoutTime" BU_SG_REL_ EPS SG_ 292 Checksum_YAW_1 100;
BA_REL_ "GenSigTimeoutTime" BU_SG_REL_ IBC SG_ 292 Checksum_YAW_1 100;
BA_REL_ "GenSigTimeoutTime" BU_SG_REL_ EPS SG_ 292 Acceleration_X_ACU 100;
BA_REL_ "GenSigTimeoutTime" BU_SG_REL_ IBC SG_ 292 Acceleration_X_ACU 100;
BA_REL_ "GenSigTimeoutTime" BU_SG_REL_ EPS SG_ 292 Acceleration_Y_ACU 100;
BA_REL_ "GenSigTimeoutTime" BU_SG_REL_ IBC SG_ 292 Acceleration_Y_ACU 100;
BA_REL_ "GenSigTimeoutTime" BU_SG_REL_ EPS SG_ 292 YawRate_ACU 100;
BA_REL_ "GenSigTimeoutTime" BU_SG_REL_ IBC SG_ 292 YawRate_ACU 100;
BA_REL_ "GenSigTimeoutTime" BU_SG_REL_ EPS SG_ 292 LatSensorSt 100;
BA_REL_ "GenSigTimeoutTime" BU_SG_REL_ IBC SG_ 292 LatSensorSt 100;
BA_REL_ "GenSigTimeoutTime" BU_SG_REL_ EPS SG_ 292 LgtSensorSt 100;
BA_REL_ "GenSigTimeoutTime" BU_SG_REL_ IBC SG_ 292 LgtSensorSt 100;
BA_REL_ "GenSigTimeoutTime" BU_SG_REL_ EPS SG_ 292 YRSCalibrateSt_ACU 100;
BA_REL_ "GenSigTimeoutTime" BU_SG_REL_ IBC SG_ 292 YRSCalibrateSt_ACU 100;
BA_REL_ "GenSigTimeoutTime" BU_SG_REL_ EPS SG_ 292 YRSSt_ACU 100;
BA_REL_ "GenSigTimeoutTime" BU_SG_REL_ IBC SG_ 292 YRSSt_ACU 100;
BA_REL_ "GenSigTimeoutTime" BU_SG_REL_ EPS SG_ 292 LiveCounter_YAW_1 100;
BA_REL_ "GenSigTimeoutTime" BU_SG_REL_ IBC SG_ 292 LiveCounter_YAW_1 100;
BA_REL_ "GenSigTimeoutTime" BU_SG_REL_ Gateway SG_ 208 Checksum_EPS1_SAS_1 100;
BA_REL_ "GenSigTimeoutTime" BU_SG_REL_ Gateway SG_ 208 EPS1_SteeringWheelAngle 100;
BA_REL_ "GenSigTimeoutTime" BU_SG_REL_ Gateway SG_ 208 EPS1_SteeringWheelAngleSign 100;
BA_REL_ "GenSigTimeoutTime" BU_SG_REL_ Gateway SG_ 208 EPS1_SteeringWheelSpeed 100;
BA_REL_ "GenSigTimeoutTime" BU_SG_REL_ Gateway SG_ 208 EPS1_SteeringWheelSpeedSign 100;
BA_REL_ "GenSigTimeoutTime" BU_SG_REL_ Gateway SG_ 208 EPS1_SAS_St 100;
BA_REL_ "GenSigTimeoutTime" BU_SG_REL_ Gateway SG_ 208 LiveCounter_EPS1_SAS_1 100;
BA_REL_ "GenSigTimeoutTime" BU_SG_REL_ Gateway SG_ 336 Checksum_EPS_1_1 200;
BA_REL_ "GenSigTimeoutTime" BU_SG_REL_ Gateway SG_ 336 EPS_1_HandSteeringTorque 200;
BA_REL_ "GenSigTimeoutTime" BU_SG_REL_ Gateway SG_ 336 EPS_1_HandSteeringTorqueSign 200;
BA_REL_ "GenSigTimeoutTime" BU_SG_REL_ Gateway SG_ 336 EPS_1_ErrorStatus 200;
BA_REL_ "GenSigTimeoutTime" BU_SG_REL_ Gateway SG_ 336 EPS_1_ModeChangeEnable 200;
BA_REL_ "GenSigTimeoutTime" BU_SG_REL_ Gateway SG_ 336 EPS_1_HandOffStatus 200;
BA_REL_ "GenSigTimeoutTime" BU_SG_REL_ Gateway SG_ 336 EPS_1_HandOffValid 200;
BA_REL_ "GenSigTimeoutTime" BU_SG_REL_ Gateway SG_ 336 EPS_1_LKAStatus 200;
BA_REL_ "GenSigTimeoutTime" BU_SG_REL_ Gateway SG_ 336 EPS_1_A_TASSensorStatus 200;
BA_REL_ "GenSigTimeoutTime" BU_SG_REL_ Gateway SG_ 336 EPS_1_B_TASSensorStatus 200;
BA_REL_ "GenSigTimeoutTime" BU_SG_REL_ Gateway SG_ 336 EPS_1_OverlayInputTorque 200;
BA_REL_ "GenSigTimeoutTime" BU_SG_REL_ Gateway SG_ 336 EPS_1_OverlayInputTorqueSign 200;
BA_REL_ "GenSigTimeoutTime" BU_SG_REL_ Gateway SG_ 336 EPS_1_AbortFeedback 200;
BA_REL_ "GenSigTimeoutTime" BU_SG_REL_ Gateway SG_ 336 EPS_1_WorkingMode_DMS 200;
BA_REL_ "GenSigTimeoutTime" BU_SG_REL_ Gateway SG_ 336 LiveCounter_EPS_1_1 200;
BA_REL_ "GenSigTimeoutTime" BU_SG_REL_ Gateway SG_ 337 Checksum_EPS_1_2 200;
BA_REL_ "GenSigTimeoutTime" BU_SG_REL_ Gateway SG_ 337 EPS_1_SACCStatus 200;
BA_REL_ "GenSigTimeoutTime" BU_SG_REL_ Gateway SG_ 337 EPS_1_NOPStatus 200;
BA_REL_ "GenSigTimeoutTime" BU_SG_REL_ Gateway SG_ 337 EPS_1_NGPStatus 200;
BA_REL_ "GenSigTimeoutTime" BU_SG_REL_ Gateway SG_ 337 EPS_1_APAStatus 200;
BA_REL_ "GenSigTimeoutTime" BU_SG_REL_ Gateway SG_ 337 EPS_1_RPAStatus 200;
BA_REL_ "GenSigTimeoutTime" BU_SG_REL_ Gateway SG_ 337 EPS_1_AVPStatus 200;
BA_REL_ "GenSigTimeoutTime" BU_SG_REL_ Gateway SG_ 337 EPS_1_EMAStatus 200;
BA_REL_ "GenSigTimeoutTime" BU_SG_REL_ Gateway SG_ 337 EPS_1_DegradeLevel_HAD 200;
BA_REL_ "GenSigTimeoutTime" BU_SG_REL_ Gateway SG_ 337 EPS_1_PullingReminder 200;
BA_REL_ "GenSigTimeoutTime" BU_SG_REL_ Gateway SG_ 337 EPS_1_AutoDrivingMode 200;
BA_REL_ "GenSigTimeoutTime" BU_SG_REL_ Gateway SG_ 337 EPS_1_PullingTorque 200;
BA_REL_ "GenSigTimeoutTime" BU_SG_REL_ Gateway SG_ 337 EPS_1_PullingTorqueSign 200;
BA_REL_ "GenSigTimeoutTime" BU_SG_REL_ Gateway SG_ 337 EPS_1_L3BackupStatus 200;
BA_REL_ "GenSigTimeoutTime" BU_SG_REL_ Gateway SG_ 337 LiveCounter_EPS_1_2 200;
BA_REL_ "GenSigTimeoutTime" BU_SG_REL_ Gateway SG_ 443 checksum_EPS_1_Test 200;
BA_REL_ "GenSigTimeoutTime" BU_SG_REL_ Gateway SG_ 443 EPS_1_A_ElectricLoad 200;
BA_REL_ "GenSigTimeoutTime" BU_SG_REL_ Gateway SG_ 443 EPS_1_A_Motor_Angle 200;
BA_REL_ "GenSigTimeoutTime" BU_SG_REL_ Gateway SG_ 443 EPS_1_A_Motor_Angle_Sign 200;
BA_REL_ "GenSigTimeoutTime" BU_SG_REL_ Gateway SG_ 443 EPS_1_A_Motor_AngleSpeed 200;
BA_REL_ "GenSigTimeoutTime" BU_SG_REL_ Gateway SG_ 443 EPS_1_A_Motor_AngleSpeed_Sign 200;
BA_REL_ "GenSigTimeoutTime" BU_SG_REL_ Gateway SG_ 443 EPS_1_A_Motor_Torque 200;
BA_REL_ "GenSigTimeoutTime" BU_SG_REL_ Gateway SG_ 443 EPS_1_A_Motor_Torque_Sign 200;
BA_REL_ "GenSigTimeoutTime" BU_SG_REL_ Gateway SG_ 443 LiveCounter_EPS_1_Test 200;
BA_REL_ "GenSigTimeoutTime" BU_SG_REL_ Gateway SG_ 1210 SoftwareNumber_EPS 50000;
BA_REL_ "GenSigTimeoutTime" BU_SG_REL_ Gateway SG_ 1210 HardwareRelated_ConfigID_EPS 50000;
BA_REL_ "GenSigTimeoutTime" BU_SG_REL_ Gateway SG_ 192 Checksum_ABS_1 100;
BA_REL_ "GenSigTimeoutTime" BU_SG_REL_ Gateway SG_ 192 WheelSpeed_FL 100;
BA_REL_ "GenSigTimeoutTime" BU_SG_REL_ Gateway SG_ 192 WheelSpeed_FR 100;
BA_REL_ "GenSigTimeoutTime" BU_SG_REL_ Gateway SG_ 192 WheelSpeed_RL 100;
BA_REL_ "GenSigTimeoutTime" BU_SG_REL_ Gateway SG_ 192 WheelSpeed_RR 100;
BA_REL_ "GenSigTimeoutTime" BU_SG_REL_ Gateway SG_ 192 WheelPulse_FL 100;
BA_REL_ "GenSigTimeoutTime" BU_SG_REL_ Gateway SG_ 192 WheelPulse_FR 100;
BA_REL_ "GenSigTimeoutTime" BU_SG_REL_ Gateway SG_ 192 WheelPulse_RL 100;
BA_REL_ "GenSigTimeoutTime" BU_SG_REL_ Gateway SG_ 192 WheelPulse_RR 100;
BA_REL_ "GenSigTimeoutTime" BU_SG_REL_ Gateway SG_ 192 WheelSpeedDirection_FL 100;
BA_REL_ "GenSigTimeoutTime" BU_SG_REL_ Gateway SG_ 192 WheelSpeedDirection_FR 100;
BA_REL_ "GenSigTimeoutTime" BU_SG_REL_ Gateway SG_ 192 WheelSpeedDirection_RL 100;
BA_REL_ "GenSigTimeoutTime" BU_SG_REL_ Gateway SG_ 192 WheelSpeedDirection_RR 100;
BA_REL_ "GenSigTimeoutTime" BU_SG_REL_ Gateway SG_ 192 WheelSpeedDirection_FL_Q 100;
BA_REL_ "GenSigTimeoutTime" BU_SG_REL_ Gateway SG_ 192 WheelSpeedDirection_FR_Q 100;
BA_REL_ "GenSigTimeoutTime" BU_SG_REL_ Gateway SG_ 192 WheelSpeedDirection_RL_Q 100;
BA_REL_ "GenSigTimeoutTime" BU_SG_REL_ Gateway SG_ 192 WheelSpeedDirection_RR_Q 100;
BA_REL_ "GenSigTimeoutTime" BU_SG_REL_ Gateway SG_ 192 VehicleSpeed 100;
BA_REL_ "GenSigTimeoutTime" BU_SG_REL_ Gateway SG_ 192 VehiclSpeed_Q 100;
BA_REL_ "GenSigTimeoutTime" BU_SG_REL_ Gateway SG_ 192 DrivingDirection 100;
BA_REL_ "GenSigTimeoutTime" BU_SG_REL_ Gateway SG_ 192 DrivingDirection_Q 100;
BA_REL_ "GenSigTimeoutTime" BU_SG_REL_ Gateway SG_ 192 BrakeTorqueOnWheels 100;
BA_REL_ "GenSigTimeoutTime" BU_SG_REL_ Gateway SG_ 192 EstimatedWheelPressure_FL 100;
BA_REL_ "GenSigTimeoutTime" BU_SG_REL_ Gateway SG_ 192 EstimatedWheelPressure_FR 100;
BA_REL_ "GenSigTimeoutTime" BU_SG_REL_ Gateway SG_ 192 EstimatedWheelPressure_RL 100;
BA_REL_ "GenSigTimeoutTime" BU_SG_REL_ Gateway SG_ 192 EstimatedWheelPressure_RR 100;
BA_REL_ "GenSigTimeoutTime" BU_SG_REL_ Gateway SG_ 192 LiveCounter_ABS_1 100;
BA_REL_ "GenSigTimeoutTime" BU_SG_REL_ Gateway SG_ 195 Checksum_ESC_1_W 100;
BA_REL_ "GenSigTimeoutTime" BU_SG_REL_ Gateway SG_ 195 TorqueReductionFast_TCS_FrontWhe 100;
BA_REL_ "GenSigTimeoutTime" BU_SG_REL_ Gateway SG_ 195 TorqueIncrease_MSR_FrontWheel 100;
BA_REL_ "GenSigTimeoutTime" BU_SG_REL_ Gateway SG_ 195 TorqueReductionFast_TCS_RearWhee 100;
BA_REL_ "GenSigTimeoutTime" BU_SG_REL_ Gateway SG_ 195 TorqueIncrease_MSR_RearWheel 100;
BA_REL_ "GenSigTimeoutTime" BU_SG_REL_ Gateway SG_ 195 ESC_RegenerationTorqueRequest 100;
BA_REL_ "GenSigTimeoutTime" BU_SG_REL_ Gateway SG_ 195 ESC_RegenerationTorqueRequest_Q 100;
BA_REL_ "GenSigTimeoutTime" BU_SG_REL_ Gateway SG_ 195 TorqReductionFastSt_TCS_FrontWhe 100;
BA_REL_ "GenSigTimeoutTime" BU_SG_REL_ Gateway SG_ 195 TorqueIncreaseSt_MSR_FrontWheel 100;
BA_REL_ "GenSigTimeoutTime" BU_SG_REL_ Gateway SG_ 195 TorqReductionFastSt_TCS_RearWhee 100;
BA_REL_ "GenSigTimeoutTime" BU_SG_REL_ Gateway SG_ 195 TorqueIncreaseSt_MSR_RearWheel 100;
BA_REL_ "GenSigTimeoutTime" BU_SG_REL_ Gateway SG_ 195 ESC_StatusRegenerationTorqueRequ 100;
BA_REL_ "GenSigTimeoutTime" BU_SG_REL_ Gateway SG_ 195 ESC_FrontBiasMax 100;
BA_REL_ "GenSigTimeoutTime" BU_SG_REL_ Gateway SG_ 195 ESC_RearBiasMax 100;
BA_REL_ "GenSigTimeoutTime" BU_SG_REL_ Gateway SG_ 195 LiveCounter_ESC_1_W 100;
BA_REL_ "GenSigTimeoutTime" BU_SG_REL_ Gateway SG_ 306 Checksum_ESC_2_1 100;
BA_REL_ "GenSigTimeoutTime" BU_SG_REL_ Gateway SG_ 306 WorkingSt_ESC 100;
BA_REL_ "GenSigTimeoutTime" BU_SG_REL_ Gateway SG_ 306 ErrorSt_ESC 100;
BA_REL_ "GenSigTimeoutTime" BU_SG_REL_ Gateway SG_ 306 Intervention_ESC 100;
BA_REL_ "GenSigTimeoutTime" BU_SG_REL_ Gateway SG_ 306 ErrorSt_ABS 100;
BA_REL_ "GenSigTimeoutTime" BU_SG_REL_ Gateway SG_ 306 Intervention_ABS 100;
BA_REL_ "GenSigTimeoutTime" BU_SG_REL_ Gateway SG_ 306 ESC_Status_RollerBenchMode 100;
BA_REL_ "GenSigTimeoutTime" BU_SG_REL_ Gateway SG_ 306 Intervention_TCS 100;
BA_REL_ "GenSigTimeoutTime" BU_SG_REL_ Gateway SG_ 306 ErrorSt_EBD 100;
BA_REL_ "GenSigTimeoutTime" BU_SG_REL_ Gateway SG_ 306 AvailableSt_CDP 100;
BA_REL_ "GenSigTimeoutTime" BU_SG_REL_ Gateway SG_ 306 Intervention_CDP 100;
BA_REL_ "GenSigTimeoutTime" BU_SG_REL_ Gateway SG_ 306 AvailableSt_HHC 100;
BA_REL_ "GenSigTimeoutTime" BU_SG_REL_ Gateway SG_ 306 Intervention_HHC 100;
BA_REL_ "GenSigTimeoutTime" BU_SG_REL_ Gateway SG_ 306 AvailableSt_HDC 100;
BA_REL_ "GenSigTimeoutTime" BU_SG_REL_ Gateway SG_ 306 WorkingSt_HDC 100;
BA_REL_ "GenSigTimeoutTime" BU_SG_REL_ Gateway SG_ 306 ErrorSt_AVH 100;
BA_REL_ "GenSigTimeoutTime" BU_SG_REL_ Gateway SG_ 306 WorkingSt_AVH 100;
BA_REL_ "GenSigTimeoutTime" BU_SG_REL_ Gateway SG_ 306 AvailableSt_AEB 100;
BA_REL_ "GenSigTimeoutTime" BU_SG_REL_ Gateway SG_ 306 Intervention_AEB 100;
BA_REL_ "GenSigTimeoutTime" BU_SG_REL_ Gateway SG_ 306 AvailableSt_ABP 100;
BA_REL_ "GenSigTimeoutTime" BU_SG_REL_ Gateway SG_ 306 Intervention_ABP 100;
BA_REL_ "GenSigTimeoutTime" BU_SG_REL_ Gateway SG_ 306 AvailableSt_AWB 100;
BA_REL_ "GenSigTimeoutTime" BU_SG_REL_ Gateway SG_ 306 Intervention_AWB 100;
BA_REL_ "GenSigTimeoutTime" BU_SG_REL_ Gateway SG_ 306 AvailableSt_HBA 100;
BA_REL_ "GenSigTimeoutTime" BU_SG_REL_ Gateway SG_ 306 Intervention_HBA 100;
BA_REL_ "GenSigTimeoutTime" BU_SG_REL_ Gateway SG_ 306 Intervention_EmergencyBrake 100;
BA_REL_ "GenSigTimeoutTime" BU_SG_REL_ Gateway SG_ 306 VehicleStandstillSt_ESC 100;
BA_REL_ "GenSigTimeoutTime" BU_SG_REL_ Gateway SG_ 306 BrakeLightCtrlCmd_ESC 100;
BA_REL_ "GenSigTimeoutTime" BU_SG_REL_ Gateway SG_ 306 Intervention_BTCS_F 100;
BA_REL_ "GenSigTimeoutTime" BU_SG_REL_ Gateway SG_ 306 Intervention_BTCS_R 100;
BA_REL_ "GenSigTimeoutTime" BU_SG_REL_ Gateway SG_ 306 AvailableSt_MSR 100;
BA_REL_ "GenSigTimeoutTime" BU_SG_REL_ Gateway SG_ 306 RoughRoadLevel 100;
BA_REL_ "GenSigTimeoutTime" BU_SG_REL_ Gateway SG_ 306 BrakeHoldActive 100;
BA_REL_ "GenSigTimeoutTime" BU_SG_REL_ Gateway SG_ 306 ParkingRequestToEPB 100;
BA_REL_ "GenSigTimeoutTime" BU_SG_REL_ Gateway SG_ 306 WorkingMode_ESC 100;
BA_REL_ "GenSigTimeoutTime" BU_SG_REL_ Gateway SG_ 306 ModeChangeEnable_ESC 100;
BA_REL_ "GenSigTimeoutTime" BU_SG_REL_ Gateway SG_ 306 WorkingSt_CST 100;
BA_REL_ "GenSigTimeoutTime" BU_SG_REL_ Gateway SG_ 306 LiveCounter_ESC_2_1 100;
BA_REL_ "GenSigTimeoutTime" BU_SG_REL_ Gateway SG_ 312 Checksum_ESC_5_1 200;
BA_REL_ "GenSigTimeoutTime" BU_SG_REL_ Gateway SG_ 312 ESC_TorqueReq_VMC_1 200;
BA_REL_ "GenSigTimeoutTime" BU_SG_REL_ Gateway SG_ 312 ESC_TorqueReqSt_VMC_1 200;
BA_REL_ "GenSigTimeoutTime" BU_SG_REL_ Gateway SG_ 312 ESC_TargetGearReq_VMC_1 200;
BA_REL_ "GenSigTimeoutTime" BU_SG_REL_ Gateway SG_ 312 ESC_TargetGearReqEnable_VMC_1 200;
BA_REL_ "GenSigTimeoutTime" BU_SG_REL_ Gateway SG_ 312 ESC_SuspendStatus_L2 200;
BA_REL_ "GenSigTimeoutTime" BU_SG_REL_ Gateway SG_ 312 ESC_EPBAvailableSt_L3 200;
BA_REL_ "GenSigTimeoutTime" BU_SG_REL_ Gateway SG_ 312 ESC_CommunicationSt_L3 200;
BA_REL_ "GenSigTimeoutTime" BU_SG_REL_ Gateway SG_ 312 ESC_UsedChannel_L3 200;
BA_REL_ "GenSigTimeoutTime" BU_SG_REL_ Gateway SG_ 312 ESC_ControllerReleaseSt_L3 200;
BA_REL_ "GenSigTimeoutTime" BU_SG_REL_ Gateway SG_ 312 ESC_SuspendStatusByDriver_L3 200;
BA_REL_ "GenSigTimeoutTime" BU_SG_REL_ Gateway SG_ 312 ESC_SuspendStatusByOther_L3 200;
BA_REL_ "GenSigTimeoutTime" BU_SG_REL_ Gateway SG_ 312 ESC_VLC_Error_L12 200;
BA_REL_ "GenSigTimeoutTime" BU_SG_REL_ Gateway SG_ 312 ESC_VLCSt 200;
BA_REL_ "GenSigTimeoutTime" BU_SG_REL_ Gateway SG_ 312 ESC_VMC_Error_L3 200;
BA_REL_ "GenSigTimeoutTime" BU_SG_REL_ Gateway SG_ 312 ESC_AutoDriving_LC_Brakemode 200;
BA_REL_ "GenSigTimeoutTime" BU_SG_REL_ Gateway SG_ 312 ESC_AutoPark_LC_HPA_Avail 200;
BA_REL_ "GenSigTimeoutTime" BU_SG_REL_ Gateway SG_ 312 ESC_AutoPark_LCSt 200;
BA_REL_ "GenSigTimeoutTime" BU_SG_REL_ Gateway SG_ 312 ESC_AutoPark_LC_APA_Avail 200;
BA_REL_ "GenSigTimeoutTime" BU_SG_REL_ Gateway SG_ 312 ESC_AutoPark_LC_RPA_Avail 200;
BA_REL_ "GenSigTimeoutTime" BU_SG_REL_ Gateway SG_ 312 ESC_AutoPark_LC_AVP_Avail 200;
BA_REL_ "GenSigTimeoutTime" BU_SG_REL_ Gateway SG_ 312 ESC_AutoPark_LCFailureSt 200;
BA_REL_ "GenSigTimeoutTime" BU_SG_REL_ Gateway SG_ 312 ESC_AutoPark_LC_BrakeMode 200;
BA_REL_ "GenSigTimeoutTime" BU_SG_REL_ Gateway SG_ 312 ESC_HDCActiveForbidden 200;
BA_REL_ "GenSigTimeoutTime" BU_SG_REL_ Gateway SG_ 312 ESC_ESCOffForbidden 200;
BA_REL_ "GenSigTimeoutTime" BU_SG_REL_ Gateway SG_ 312 ESC_AVHActiveForbidden 200;
BA_REL_ "GenSigTimeoutTime" BU_SG_REL_ Gateway SG_ 312 ESC_ShutOffFinished 200;
BA_REL_ "GenSigTimeoutTime" BU_SG_REL_ Gateway SG_ 312 ESC_BrakePadelOverride 200;
BA_REL_ "GenSigTimeoutTime" BU_SG_REL_ Gateway SG_ 312 LiveCounter_ESC_5_1 200;
BA_REL_ "GenSigTimeoutTime" BU_SG_REL_ Gateway SG_ 193 Checksum_IBC_1 100;
BA_REL_ "GenSigTimeoutTime" BU_SG_REL_ Gateway SG_ 193 IBC_SimulatorPressure 100;
BA_REL_ "GenSigTimeoutTime" BU_SG_REL_ Gateway SG_ 193 IBC_SimulatorPressureSt 100;
BA_REL_ "GenSigTimeoutTime" BU_SG_REL_ Gateway SG_ 193 IBC_SystemStatus 100;
BA_REL_ "GenSigTimeoutTime" BU_SG_REL_ Gateway SG_ 193 IBC_PlungerPressure 100;
BA_REL_ "GenSigTimeoutTime" BU_SG_REL_ Gateway SG_ 193 IBC_PlungerPressureSt 100;
BA_REL_ "GenSigTimeoutTime" BU_SG_REL_ Gateway SG_ 193 IBC_BrakePedalStatus_Q 100;
BA_REL_ "GenSigTimeoutTime" BU_SG_REL_ Gateway SG_ 193 IBC_InputRodStroke 100;
BA_REL_ "GenSigTimeoutTime" BU_SG_REL_ Gateway SG_ 193 IBC_InputRodStrokeSt 100;
BA_REL_ "GenSigTimeoutTime" BU_SG_REL_ Gateway SG_ 193 IBC_BrakeFluidWarning 100;
BA_REL_ "GenSigTimeoutTime" BU_SG_REL_ Gateway SG_ 193 IBC_BrakePedalStatus 100;
BA_REL_ "GenSigTimeoutTime" BU_SG_REL_ Gateway SG_ 193 TwoFootBrakeSt 100;
BA_REL_ "GenSigTimeoutTime" BU_SG_REL_ Gateway SG_ 193 DegradedBBFWarning 100;
BA_REL_ "GenSigTimeoutTime" BU_SG_REL_ Gateway SG_ 193 IBC_MILInfo 100;
BA_REL_ "GenSigTimeoutTime" BU_SG_REL_ Gateway SG_ 193 FWAWarning 100;
BA_REL_ "GenSigTimeoutTime" BU_SG_REL_ Gateway SG_ 193 IBC_RearWheelAngleRequest 100;
BA_REL_ "GenSigTimeoutTime" BU_SG_REL_ Gateway SG_ 193 IBC_RearWheelAngleRequestSt 100;
BA_REL_ "GenSigTimeoutTime" BU_SG_REL_ Gateway SG_ 193 IBC_VDCActive 100;
BA_REL_ "GenSigTimeoutTime" BU_SG_REL_ Gateway SG_ 193 LiveCounter_IBC_1 100;
BA_REL_ "GenSigTimeoutTime" BU_SG_REL_ Gateway SG_ 513 IBCdata 1000;
BA_REL_ "GenSigTimeoutTime" BU_SG_REL_ Gateway SG_ 1381 SECOC_FVReqCode_IBC 500;
BA_REL_ "GenSigTimeoutTime" BU_SG_REL_ Gateway SG_ 1260 SoftwareNumber_IBC 50000;
BA_REL_ "GenSigTimeoutTime" BU_SG_REL_ Gateway SG_ 1260 HardwareRelated_ConfigID_IBC 50000;
BA_REL_ "GenSigTimeoutTime" BU_SG_REL_ Gateway SG_ 1199 SoftwareNumber_RBU 50000;
BA_REL_ "GenSigTimeoutTime" BU_SG_REL_ Gateway SG_ 1199 HardwareRelated_ConfigID_RBU 50000;
BA_REL_ "GenSigTimeoutTime" BU_SG_REL_ Gateway SG_ 169 Checksum_RBU_1 100;
BA_REL_ "GenSigTimeoutTime" BU_SG_REL_ Gateway SG_ 169 RBU_WheelSpeed_FL 100;
BA_REL_ "GenSigTimeoutTime" BU_SG_REL_ Gateway SG_ 169 RBU_WheelSpeed_FR 100;
BA_REL_ "GenSigTimeoutTime" BU_SG_REL_ Gateway SG_ 169 RBU_WheelSpeed_RL 100;
BA_REL_ "GenSigTimeoutTime" BU_SG_REL_ Gateway SG_ 169 RBU_WheelSpeed_RR 100;
BA_REL_ "GenSigTimeoutTime" BU_SG_REL_ Gateway SG_ 169 RBU_ErrorSt_SBS 100;
BA_REL_ "GenSigTimeoutTime" BU_SG_REL_ Gateway SG_ 169 RBU_Intervention_SBS 100;
BA_REL_ "GenSigTimeoutTime" BU_SG_REL_ Gateway SG_ 169 RBU_EPBAvailableSt_L3 100;
BA_REL_ "GenSigTimeoutTime" BU_SG_REL_ Gateway SG_ 169 RBU_UsedChannel_L3 100;
BA_REL_ "GenSigTimeoutTime" BU_SG_REL_ Gateway SG_ 169 RBU_ControllerReleaseSt_L3 100;
BA_REL_ "GenSigTimeoutTime" BU_SG_REL_ Gateway SG_ 169 RBU_SuspendStatusByDriver_L3 100;
BA_REL_ "GenSigTimeoutTime" BU_SG_REL_ Gateway SG_ 169 RBU_BrakePedalStatus_Q 100;
BA_REL_ "GenSigTimeoutTime" BU_SG_REL_ Gateway SG_ 169 RBU_BrakePedalStatus 100;
BA_REL_ "GenSigTimeoutTime" BU_SG_REL_ Gateway SG_ 169 RBU_VLCSt 100;
BA_REL_ "GenSigTimeoutTime" BU_SG_REL_ Gateway SG_ 169 RBU_VMC_Error_L3 100;
BA_REL_ "GenSigTimeoutTime" BU_SG_REL_ Gateway SG_ 169 RBU_DrivingDirection 100;
BA_REL_ "GenSigTimeoutTime" BU_SG_REL_ Gateway SG_ 169 RBU_VehicleSpeed 100;
BA_REL_ "GenSigTimeoutTime" BU_SG_REL_ Gateway SG_ 169 RBU_TargetGearReq_VMC_1 100;
BA_REL_ "GenSigTimeoutTime" BU_SG_REL_ Gateway SG_ 169 RBU_TargetGearReqEnable_VMC_1 100;
BA_REL_ "GenSigTimeoutTime" BU_SG_REL_ Gateway SG_ 169 RBU_VehicleStandstillSt 100;
BA_REL_ "GenSigTimeoutTime" BU_SG_REL_ Gateway SG_ 169 RBU_BrakeLightCtrlCmd 100;
BA_REL_ "GenSigTimeoutTime" BU_SG_REL_ Gateway SG_ 169 LiveCounter_RBU_1 100;
BA_REL_ "GenSigTimeoutTime" BU_SG_REL_ Gateway SG_ 1382 SECOC_FVReqCode_RBU 500;
BA_REL_ "GenSigTimeoutTime" BU_SG_REL_ Gateway SG_ 1214 SoftwareNumber_RWS 50000;
BA_REL_ "GenSigTimeoutTime" BU_SG_REL_ Gateway SG_ 1214 HardwareRelated_ConfigID_RWS 50000;
BA_REL_ "GenSigTimeoutTime" BU_SG_REL_ Gateway SG_ 188 Checksum_RWS_1 100;
BA_REL_ "GenSigTimeoutTime" BU_SG_REL_ Gateway SG_ 188 RearWheelAngle 100;
BA_REL_ "GenSigTimeoutTime" BU_SG_REL_ Gateway SG_ 188 RearWheelAngle_QF 100;
BA_REL_ "GenSigTimeoutTime" BU_SG_REL_ Gateway SG_ 188 RearWheelAngleSpeed 100;
BA_REL_ "GenSigTimeoutTime" BU_SG_REL_ Gateway SG_ 188 WorkingSt_RWS 100;
BA_REL_ "GenSigTimeoutTime" BU_SG_REL_ Gateway SG_ 188 ErrorSt_RWS 100;
BA_REL_ "GenSigTimeoutTime" BU_SG_REL_ Gateway SG_ 188 LiveCounter_RWS_1 100;
BA_REL_ "GenSigTimeoutTime" BU_SG_REL_ Gateway SG_ 188 SECOC_FV_RWS_1 100;
BA_REL_ "GenSigTimeoutTime" BU_SG_REL_ Gateway SG_ 188 SECOC_TMAC_RWS_1 100;
BA_REL_ "GenSigTimeoutTime" BU_SG_REL_ Gateway SG_ 189 MaxAngle_RWS 100;
BA_REL_ "GenSigTimeoutTime" BU_SG_REL_ Gateway SG_ 189 MaxAngleGrad_RWS 100;
BA_REL_ "GenSigTimeoutTime" BU_SG_REL_ Gateway SG_ 1383 SECOC_FVReqCode_RWS 500;
BA_REL_ "GenSigTimeoutTime" BU_SG_REL_ Gateway SG_ 222 PbcOutActuatorState_S 100;
BA_REL_ "GenSigTimeoutTime" BU_SG_REL_ Gateway SG_ 222 PbcOutPadAdjustmentRequest_S 100;
BA_REL_ "GenSigTimeoutTime" BU_SG_REL_ Gateway SG_ 222 PbcInHostAvailability_S 100;
BA_REL_ "GenSigTimeoutTime" BU_SG_REL_ Gateway SG_ 222 PbcInApplyReleaseRequest_S 100;
BA_REL_ "GenSigTimeoutTime" BU_SG_REL_ Gateway SG_ 222 PbcInRollerbenchActive_S 100;
BA_REL_ "GenSigTimeoutTime" BU_SG_REL_ Gateway SG_ 222 PbcInDriveAwayIntentionIndi_0000 100;
BA_REL_ "GenSigTimeoutTime" BU_SG_REL_ Gateway SG_ 222 PbcEnableLineLock_S 100;
BA_REL_ "GenSigTimeoutTime" BU_SG_REL_ Gateway SG_ 222 PbcEnableLineRelease_S 100;
BA_REL_ "GenSigTimeoutTime" BU_SG_REL_ Gateway SG_ 222 EpbDegradedMode_S 100;
BA_REL_ "GenSigTimeoutTime" BU_SG_REL_ Gateway SG_ 222 PbcDynApplyControlState_S 100;
BA_REL_ "GenSigTimeoutTime" BU_SG_REL_ Gateway SG_ 222 PbcRollerbenchApplyControlS_0000 100;
BA_REL_ "GenSigTimeoutTime" BU_SG_REL_ Gateway SG_ 222 IsRelTchPt_S 100;
BA_REL_ "GenSigTimeoutTime" BU_SG_REL_ Gateway SG_ 222 IsRWAAppEn_S 100;
BA_REL_ "GenSigTimeoutTime" BU_SG_REL_ Gateway SG_ 222 IsRWARelEn_S 100;
BA_REL_ "GenSigTimeoutTime" BU_SG_REL_ Gateway SG_ 222 RWACntrStpApp_S 100;
BA_REL_ "GenSigTimeoutTime" BU_SG_REL_ Gateway SG_ 222 CntrRWAAppHld_S 100;
BA_REL_ "GenSigTimeoutTime" BU_SG_REL_ Gateway SG_ 222 PbcRWAControlState_S 100;
VAL_ 688 VDC_IgnitionOffTime 4095 "SNA" ;
VAL_ 688 VDC_RemoteVehicleMode 1 "Remote_Mode" 0 "Normal_Mode" ;
VAL_ 688 VDC_OTAMode 7 "Reserved" 6 "Reserved" 5 "Reserved" 4 "Reserved" 3 "Reserved" 2 "Reserved" 1 "OTA_Mode" 0 "Normal_Mode" ;
VAL_ 688 VDC_PowerMode 15 "Invalid_value" 14 "Reserved" 13 "Reserved" 12 "Reserved" 11 "Reserved" 10 "Reserved" 9 "Reserved" 8 "Reserved" 7 "Reserved" 6 "Driving" 5 "Pre_On" 4 "Standby" 3 "Pre_Off" 2 "Awake" 1 "Sleep" 0 "Deep_Sleep" ;
VAL_ 292 Acceleration_X_ACU 4095 "SNA" ;
VAL_ 292 Acceleration_Y_ACU 4095 "SNA" ;
VAL_ 292 YawRate_ACU 65535 "SNA" ;
VAL_ 292 LatSensorSt 3 "Initializing" 2 "Not_Used" 1 "Valid" 0 "Invalid" ;
VAL_ 292 LgtSensorSt 3 "Initializing" 2 "Not_Used" 1 "Valid" 0 "Invalid" ;
VAL_ 292 YRSCalibrateSt_ACU 1 "Calibrated" 0 "Not_Calibrated" ;
VAL_ 292 YRSSt_ACU 3 "Initializing" 2 "Not_Used" 1 "Valid" 0 "Invalid" ;
VAL_ 208 EPS1_SteeringWheelAngle 32767 "SNA" ;
VAL_ 208 EPS1_SteeringWheelAngleSign 1 "Right" 0 "Left" ;
VAL_ 208 EPS1_SteeringWheelSpeed 32767 "SNA" ;
VAL_ 208 EPS1_SteeringWheelSpeedSign 1 "Right" 0 "Left" ;
VAL_ 208 EPS1_SAS_St 3 "Angle signal invalid" 2 "Angle signal (Pinion angle) is ASILB level" 1 "Angel sensor is on De-Calibration status" 0 "Angle signal(Pinion angle)is ASILD level" ;
VAL_ 336 EPS_1_HandSteeringTorque 1023 "SNA" ;
VAL_ 336 EPS_1_HandSteeringTorqueSign 1 "Right_(Negative)" 0 "Left_(Positive)" ;
VAL_ 336 EPS_1_ErrorStatus 3 "Not_Used" 2 "Critical_Error(lose)" 1 "General_Error(Derate)" 0 "No_Error" ;
VAL_ 336 EPS_1_ModeChangeEnable 1 "Enable" 0 "Disable" ;
VAL_ 336 EPS_1_HandOffStatus 1 "Hands_On" 0 "Hands_Off" ;
VAL_ 336 EPS_1_HandOffValid 1 "Invalid" 0 "Valid" ;
VAL_ 336 EPS_1_LKAStatus 7 "Reserved" 6 "Reserved" 5 "Transit" 4 "Not_configured" 3 "Permanently_fail" 2 "Active" 1 "Available_for_control" 0 "Temporary_inhibit" ;
VAL_ 336 EPS_1_A_TASSensorStatus 1 "Error" 0 "No_error" ;
VAL_ 336 EPS_1_B_TASSensorStatus 1 "Error" 0 "No_error" ;
VAL_ 336 EPS_1_OverlayInputTorque 1023 "SNA" ;
VAL_ 336 EPS_1_OverlayInputTorqueSign 1 "Right_(Negative)" 0 "Left_(Positive)" ;
VAL_ 336 EPS_1_AbortFeedback 31 "Reserved" 30 "Reserved" 29 "Reserved" 28 "Reserved" 27 "Reserved" 26 "Reserved" 25 "Reserved" 24 "Reserved" 23 "Reserved" 22 "Reserved" 21 "Reserved" 20 "Reserved" 19 "Reserved" 18 "Reserved" 17 "Reserved" 16 "Reserved" 15 "Reserved" 14 "Reserved" 13 "Reserved" 12 "Reserved" 11 "Reserved" 10 "Reserved" 9 "Reserved" 8 "Reserved" 7 "Reserved" 6 "Reserved" 5 "Reserved" 4 "Reserved" 3 "Reserved" 2 "Irrecoverable_interruption" 1 "Recoverable_interruption" 0 "No_driving_interuption" ;
VAL_ 336 EPS_1_WorkingMode_DMS 15 "Invalid_value" 14 "Reserved" 13 "Reserved" 12 "Reserved" 11 "Reserved" 10 "Reserved" 9 "Reserved" 8 "Reserved" 7 "Reserved" 6 "Reserved" 5 "Reserved" 4 "Reserved" 3 "Reserved" 2 "Comfort" 1 "Sport" 0 "Auto" ;
VAL_ 337 EPS_1_SACCStatus 7 "Reserved" 6 "Reserved" 5 "Transit" 4 "Not_configured" 3 "Permanently_fail" 2 "Active" 1 "Available_for_control" 0 "Temporary_inhibit" ;
VAL_ 337 EPS_1_NOPStatus 7 "Reserved" 6 "Reserved" 5 "Transit" 4 "Not_configured" 3 "Permanently_fail" 2 "Active" 1 "Available_for_control" 0 "Temporary_inhibit" ;
VAL_ 337 EPS_1_NGPStatus 7 "Reserved" 6 "Reserved" 5 "Transit" 4 "Not_configured" 3 "Permanently_fail" 2 "Active" 1 "Available_for_control" 0 "Temporary_inhibit" ;
VAL_ 337 EPS_1_APAStatus 7 "Reserved" 6 "Reserved" 5 "Transit" 4 "Not_configured" 3 "Permanently_fail" 2 "Active" 1 "Available_for_control" 0 "Temporary_inhibit" ;
VAL_ 337 EPS_1_RPAStatus 7 "Reserved" 6 "Reserved" 5 "Transit" 4 "Not_configured" 3 "Permanently_fail" 2 "Active" 1 "Available_for_control" 0 "Temporary_inhibit" ;
VAL_ 337 EPS_1_AVPStatus 7 "Reserved" 6 "Reserved" 5 "Transit" 4 "Not_configured" 3 "Permanently_fail" 2 "Active" 1 "Available_for_control" 0 "Temporary_inhibit" ;
VAL_ 337 EPS_1_EMAStatus 7 "Reserved" 6 "Reserved" 5 "Transit" 4 "Not_configured" 3 "Permanently_fail" 2 "Active" 1 "Available_for_control" 0 "Temporary_inhibit" ;
VAL_ 337 EPS_1_DegradeLevel_HAD 15 "Critical_Error(lose)" 14 "Reserved" 13 "Reserved" 12 "Reserved" 11 "Reserved" 10 "Reserved" 9 "Reserved" 8 "DM8" 7 "DM7" 6 "DM6" 5 "DM5" 4 "DM4" 3 "DM3" 2 "DM2" 1 "DM1" 0 "No_Error" ;
VAL_ 337 EPS_1_PullingReminder 3 "Reserved" 2 "Reserved" 1 "Pulling" 0 "Normal" ;
VAL_ 337 EPS_1_AutoDrivingMode 15 "Reserved" 14 "Reserved" 13 "Reserved" 12 "Reserved" 11 "Reserved" 10 "L3Backup" 9 "NGP" 8 "AES" 7 "EMA" 6 "AVP" 5 "RPA" 4 "APA " 3 "NOP" 2 "SACC" 1 "LKA" 0 "Idle" ;
VAL_ 337 EPS_1_PullingTorque 1023 "SNA" ;
VAL_ 337 EPS_1_PullingTorqueSign 1 "Right_(Negative)" 0 "Left_(Positive)" ;
VAL_ 337 EPS_1_L3BackupStatus 7 "Reserved" 6 "Reserved" 5 "Transit" 4 "Not_configured" 3 "Permanently_fail" 2 "Active" 1 "Available_for_control" 0 "Temporary_inhibit" ;
VAL_ 443 EPS_1_A_ElectricLoad 255 "SNA" ;
VAL_ 443 EPS_1_A_Motor_Angle 32767 "SNA" ;
VAL_ 443 EPS_1_A_Motor_Angle_Sign 1 "right" 0 "left" ;
VAL_ 443 EPS_1_A_Motor_AngleSpeed 32767 "SNA" ;
VAL_ 443 EPS_1_A_Motor_AngleSpeed_Sign 1 "right" 0 "left" ;
VAL_ 443 EPS_1_A_Motor_Torque_Sign 1 "right" 0 "left" ;
VAL_ 192 WheelSpeed_FL 32767 "SNA" ;
VAL_ 192 WheelSpeed_FR 32767 "SNA" ;
VAL_ 192 WheelSpeed_RL 32767 "SNA" ;
VAL_ 192 WheelSpeed_RR 32767 "SNA" ;
VAL_ 192 WheelPulse_FL 255 "SNA" ;
VAL_ 192 WheelPulse_FR 255 "SNA" ;
VAL_ 192 WheelPulse_RL 255 "SNA" ;
VAL_ 192 WheelPulse_RR 255 "SNA" ;
VAL_ 192 WheelSpeedDirection_FL 3 "Undefined" 2 "Backward" 1 "Forward" 0 "Stop" ;
VAL_ 192 WheelSpeedDirection_FR 3 "Undefined" 2 "Backward" 1 "Forward" 0 "Stop" ;
VAL_ 192 WheelSpeedDirection_RL 3 "Undefined" 2 "Backward" 1 "Forward" 0 "Stop" ;
VAL_ 192 WheelSpeedDirection_RR 3 "Undefined" 2 "Backward" 1 "Forward" 0 "Stop" ;
VAL_ 192 WheelSpeedDirection_FL_Q 1 "Faulty" 0 "Normal" ;
VAL_ 192 WheelSpeedDirection_FR_Q 1 "Faulty" 0 "Normal" ;
VAL_ 192 WheelSpeedDirection_RL_Q 1 "Faulty" 0 "Normal" ;
VAL_ 192 WheelSpeedDirection_RR_Q 1 "Faulty" 0 "Normal" ;
VAL_ 192 VehicleSpeed 32767 "SNA" ;
VAL_ 192 VehiclSpeed_Q 1 "Faulty" 0 "Normal" ;
VAL_ 192 DrivingDirection 3 "Undefined" 2 "Backward" 1 "Forward" 0 "Stop" ;
VAL_ 192 DrivingDirection_Q 1 "Faulty" 0 "Normal" ;
VAL_ 192 BrakeTorqueOnWheels 4095 "SNA" ;
VAL_ 192 EstimatedWheelPressure_FL 16383 "SNA" ;
VAL_ 192 EstimatedWheelPressure_FR 16383 "SNA" ;
VAL_ 192 EstimatedWheelPressure_RL 16383 "SNA" ;
VAL_ 192 EstimatedWheelPressure_RR 16383 "SNA" ;
VAL_ 195 TorqueReductionFast_TCS_FrontWhe 8191 "SNA" ;
VAL_ 195 TorqueIncrease_MSR_FrontWheel 16383 "SNA" ;
VAL_ 195 TorqueReductionFast_TCS_RearWhee 8191 "SNA" ;
VAL_ 195 TorqueIncrease_MSR_RearWheel 16383 "SNA" ;
VAL_ 195 ESC_RegenerationTorqueRequest 8191 "SNA" ;
VAL_ 195 ESC_RegenerationTorqueRequest_Q 3 "Normal_Passive" 2 "Faulty" 1 "Normal_Active" 0 "NotInitialized" ;
VAL_ 195 TorqReductionFastSt_TCS_FrontWhe 1 "Request" 0 "No_Request" ;
VAL_ 195 TorqueIncreaseSt_MSR_FrontWheel 1 "Request" 0 "No_Request" ;
VAL_ 195 TorqReductionFastSt_TCS_RearWhee 1 "Request" 0 "No_Request" ;
VAL_ 195 TorqueIncreaseSt_MSR_RearWheel 1 "Request" 0 "No_Request" ;
VAL_ 195 ESC_StatusRegenerationTorqueRequ 1 "Request" 0 "No_Request" ;
VAL_ 195 ESC_FrontBiasMax 127 "SNA" ;
VAL_ 195 ESC_RearBiasMax 127 "SNA" ;
VAL_ 306 WorkingSt_ESC 1 "On" 0 "Off" ;
VAL_ 306 ErrorSt_ESC 1 "Error" 0 "No_Error" ;
VAL_ 306 Intervention_ESC 1 "Intervention" 0 "No_Intervention" ;
VAL_ 306 ErrorSt_ABS 1 "Error" 0 "No_Error" ;
VAL_ 306 Intervention_ABS 1 "Intervention" 0 "No_Intervention" ;
VAL_ 306 ESC_Status_RollerBenchMode 1 "Active" 0 "Inactive" ;
VAL_ 306 Intervention_TCS 1 "Intervention" 0 "No_Intervention" ;
VAL_ 306 ErrorSt_EBD 1 "Error" 0 "No_error" ;
VAL_ 306 AvailableSt_CDP 1 "Available" 0 "Not_Available" ;
VAL_ 306 Intervention_CDP 1 "Intervention" 0 "No_intervention" ;
VAL_ 306 AvailableSt_HHC 1 "Available" 0 "Not_Available" ;
VAL_ 306 Intervention_HHC 1 "Intervention" 0 "No_intervention" ;
VAL_ 306 AvailableSt_HDC 1 "Available" 0 "Not_Available" ;
VAL_ 306 WorkingSt_HDC 3 "Error" 2 "Intervention" 1 "Standby" 0 "Off" ;
VAL_ 306 ErrorSt_AVH 1 "Error" 0 "No_Error" ;
VAL_ 306 WorkingSt_AVH 3 "Inactive" 2 "Intervention" 1 "Stand_By" 0 "Off" ;
VAL_ 306 AvailableSt_AEB 1 "Available" 0 "Not_Available" ;
VAL_ 306 Intervention_AEB 1 "Intervention" 0 "No_Intervention" ;
VAL_ 306 AvailableSt_ABP 1 "Available" 0 "Not_Available" ;
VAL_ 306 Intervention_ABP 1 "Intervention" 0 "No_Intervention" ;
VAL_ 306 AvailableSt_AWB 1 "Available" 0 "Not_Available" ;
VAL_ 306 Intervention_AWB 1 "Intervention" 0 "No_intervention" ;
VAL_ 306 AvailableSt_HBA 1 "Available" 0 "Not_Available" ;
VAL_ 306 Intervention_HBA 1 "Intervention" 0 "No_Intervention" ;
VAL_ 306 Intervention_EmergencyBrake 1 "Intervention" 0 "No_intervention" ;
VAL_ 306 VehicleStandstillSt_ESC 1 "The_vehicle_is_in_standstill." 0 "The_vehicle_is_not__in_standstill." ;
VAL_ 306 BrakeLightCtrlCmd_ESC 1 "Illuminate" 0 "Not_illuminate" ;
VAL_ 306 Intervention_BTCS_F 1 "Intervention" 0 "No_Intervention" ;
VAL_ 306 Intervention_BTCS_R 1 "Intervention" 0 "No_Intervention" ;
VAL_ 306 AvailableSt_MSR 1 "Available" 0 "Not_Available" ;
VAL_ 306 RoughRoadLevel 7 "Invalid_Value" 6 "level_6" 5 "level_5" 4 "level_4" 3 "level_3" 2 "level_2" 1 "level_1" 0 "Inactive" ;
VAL_ 306 BrakeHoldActive 1 "Active" 0 "Inactive" ;
VAL_ 306 ParkingRequestToEPB 3 "Not_Used" 2 "Lock_brake_request" 1 "Release_brake_request" 0 "No_request" ;
VAL_ 306 WorkingMode_ESC 15 "Invalid_value" 14 "Reserved" 13 "Reserved" 12 "Reserved" 11 "Reserved" 10 "Reserved" 9 "Reserved" 8 "Reserved" 7 "SportPlus" 6 "Sport" 5 "Sand" 4 "MUD_Ruts" 3 "Off_road" 2 "Snow" 1 "Eco" 0 "Auto" ;
VAL_ 306 ModeChangeEnable_ESC 1 "Enable" 0 "Disable" ;
VAL_ 306 WorkingSt_CST 3 "Error" 2 "Intervention" 1 "Standby" 0 "Off" ;
VAL_ 312 ESC_TorqueReq_VMC_1 131071 "SNA" ;
VAL_ 312 ESC_TorqueReqSt_VMC_1 3 "Not_Used" 2 "Not_Used" 1 "Request" 0 "No_Request" ;
VAL_ 312 ESC_TargetGearReq_VMC_1 7 "Invalid" 6 "Not_Used" 5 "Not_Used" 4 "Target_gear_D" 3 "Target_gear_N" 2 "Target_gear_R" 1 "Target_gear_P" 0 "No_Request" ;
VAL_ 312 ESC_TargetGearReqEnable_VMC_1 1 "Enable" 0 "Not enable" ;
VAL_ 312 ESC_SuspendStatus_L2 7 "Not_Used" 6 "Not_Used" 5 "Not_Used" 4 "RampOffByDriverBrake" 3 "SuspendByDriverPropulsion" 2 "Not_Used" 1 "Not_Used" 0 "No_Request" ;
VAL_ 312 ESC_EPBAvailableSt_L3 1 "Not Available" 0 "Available" ;
VAL_ 312 ESC_CommunicationSt_L3 1 "Valid" 0 "Invalid" ;
VAL_ 312 ESC_UsedChannel_L3 3 "HAD2Com1" 2 "HAD1Com2" 1 "HAD1Com1" 0 "NoChannel" ;
VAL_ 312 ESC_ControllerReleaseSt_L3 1 "Release" 0 "NotRelease" ;
VAL_ 312 ESC_SuspendStatusByDriver_L3 3 "Not_Used" 2 "SuspendByDriverPropulsion" 1 "SuspendByDriverBrake" 0 "No Suspend" ;
VAL_ 312 ESC_SuspendStatusByOther_L3 1 "SuspendByOtherBrake(CDP)" 0 "No Suspend" ;
VAL_ 312 ESC_VLC_Error_L12 3 "Not_Used" 2 "Available" 1 "NotAvailableBySituation" 0 "NotAvailable" ;
VAL_ 312 ESC_VLCSt 3 "Not_Used" 2 "Active_L3" 1 "Active_L12" 0 "Inactivce" ;
VAL_ 312 ESC_VMC_Error_L3 7 "Not_Used" 6 "Not_Used" 5 "Not_Used" 4 "Available" 3 "AvailableWithSituationIssue" 2 "AvailableWithFault" 1 "NotAvailableBySituation" 0 "NotAvailable" ;
VAL_ 312 ESC_AutoDriving_LC_Brakemode 3 "Not_Used" 2 "Emergency" 1 "Comfortable" 0 "Inactive" ;
VAL_ 312 ESC_AutoPark_LC_HPA_Avail 3 "Available" 2 "Not_Used" 1 "Test Pending" 0 "Not_Available" ;
VAL_ 312 ESC_AutoPark_LCSt 7 "Not Used" 6 "Active_AVP" 5 "Active_RPA" 4 "Active_APA" 3 "Active_HPA" 2 "Not_Used" 1 "Standby" 0 "Not Used" ;
VAL_ 312 ESC_AutoPark_LC_APA_Avail 3 "Available" 2 "Not_Used" 1 "Not_Used" 0 "Not_Available" ;
VAL_ 312 ESC_AutoPark_LC_RPA_Avail 3 "Available" 2 "Not_Used" 1 "Test Pending" 0 "Not_Available" ;
VAL_ 312 ESC_AutoPark_LC_AVP_Avail 3 "Available" 2 "Not_Used" 1 "Test Pending" 0 "Not_Available" ;
VAL_ 312 ESC_AutoPark_LCFailureSt 15 "Error" 14 "Not_Used_15" 13 "Not_Used_14" 12 "Not_Used_13" 11 "Not_Used_12" 10 "Not_Used_11" 9 "Not_Used_10" 8 "Speed_Too_High" 7 "Parking_Triggered_Without_Secure" 6 "Not_Used_7" 5 "Not_Used_6" 4 "Not_Used_5" 3 "Unexpected_EPB_Action" 2 "Unexpected_GearPosition" 1 "Vehicle_Blocked" 0 "No_Error" ;
VAL_ 312 ESC_AutoPark_LC_BrakeMode 3 "Not_Used" 2 "Emergency" 1 "Comfortable" 0 "Inactive" ;
VAL_ 312 ESC_HDCActiveForbidden 1 "Active" 0 "Inactive" ;
VAL_ 312 ESC_ESCOffForbidden 1 "Active" 0 "Inactive" ;
VAL_ 312 ESC_AVHActiveForbidden 1 "Active" 0 "Inactive" ;
VAL_ 312 ESC_ShutOffFinished 1 "Active" 0 "Inactive" ;
VAL_ 312 ESC_BrakePadelOverride 1 "Active" 0 "Inactive" ;
VAL_ 193 IBC_SimulatorPressure 1023 "SNA" ;
VAL_ 193 IBC_SimulatorPressureSt 1 "Valid" 0 "Invalid" ;
VAL_ 193 IBC_SystemStatus 7 "Not_Used_7" 6 "Not_Used_6" 5 "Not_Used_5" 4 "Hydraulic_Backup" 3 "BBF_C1/2BoostOnly" 2 "BBF_CircuitSperation" 1 "BBF_DegradedPedalFeel" 0 "BBF_FullSy" ;
VAL_ 193 IBC_PlungerPressure 1023 "SNA" ;
VAL_ 193 IBC_PlungerPressureSt 1 "Valid" 0 "Invalid" ;
VAL_ 193 IBC_BrakePedalStatus_Q 3 "Not_Used" 2 "Full" 1 "Fault" 0 "NotInitialized" ;
VAL_ 193 IBC_InputRodStroke 1023 "SNA" ;
VAL_ 193 IBC_InputRodStrokeSt 1 "Valid" 0 "Invalid" ;
VAL_ 193 IBC_BrakeFluidWarning 3 "Invalid" 2 "BrakeFluid_Electric_error" 1 "BrakeFluid_Empty" 0 "BrakeFluid_Normal" ;
VAL_ 193 IBC_BrakePedalStatus 3 "Error" 2 "Not_Used" 1 "Actuated" 0 "Not_Actuated" ;
VAL_ 193 TwoFootBrakeSt 1 "Two_foot_brake_occur" 0 "Normal" ;
VAL_ 193 DegradedBBFWarning 1 "Warning" 0 "No_warning" ;
VAL_ 193 IBC_MILInfo 1 "Active" 0 "Inactive" ;
VAL_ 193 FWAWarning 3 "Not_Used" 2 "brake_system_over_temperature_warning_level2" 1 "brake_system_over_temperature_warning_level1" 0 "No_Fault" ;
VAL_ 193 IBC_RearWheelAngleRequest 4095 "SNA" ;
VAL_ 193 IBC_RearWheelAngleRequestSt 1 "Valid" 0 "Invalid" ;
VAL_ 193 IBC_VDCActive 1 "Valid" 0 "Invalid" ;
VAL_ 169 RBU_WheelSpeed_FL 32767 "SNA" ;
VAL_ 169 RBU_WheelSpeed_FR 32767 "SNA" ;
VAL_ 169 RBU_WheelSpeed_RL 32767 "SNA" ;
VAL_ 169 RBU_WheelSpeed_RR 32767 "SNA" ;
VAL_ 169 RBU_ErrorSt_SBS 1 "Error" 0 "No_Error" ;
VAL_ 169 RBU_Intervention_SBS 1 "Intervention" 0 "No_Intervention" ;
VAL_ 169 RBU_EPBAvailableSt_L3 1 "Not Available" 0 "Available" ;
VAL_ 169 RBU_UsedChannel_L3 3 "HAD2Com1" 2 "HAD1Com2" 1 "HAD1Com1" 0 "NoChannel" ;
VAL_ 169 RBU_ControllerReleaseSt_L3 1 "Release" 0 "NotRelease" ;
VAL_ 169 RBU_SuspendStatusByDriver_L3 3 "Not_Used" 2 "Not_Used" 1 "SuspendByDriverBrake" 0 "No Suspend" ;
VAL_ 169 RBU_BrakePedalStatus_Q 3 "Not_Used" 2 "Full" 1 "Fault" 0 "NotInitialized" ;
VAL_ 169 RBU_BrakePedalStatus 3 "Error" 2 "Not_Used" 1 "Actuated" 0 "Not_Actuated" ;
VAL_ 169 RBU_VLCSt 3 "Not_Used" 2 "Active_L3" 1 "Not_Used" 0 "Inactivce" ;
VAL_ 169 RBU_VMC_Error_L3 7 "Not_Used" 6 "Not_Used" 5 "Not_Used" 4 "Available" 3 "AvailableWithSituationIssue" 2 "AvailableWithFault" 1 "NotAvailableBySituation" 0 "NotAvailable" ;
VAL_ 169 RBU_DrivingDirection 3 "Undefined" 2 "Backward" 1 "Forward" 0 "Stop" ;
VAL_ 169 RBU_VehicleSpeed 32767 "SNA" ;
VAL_ 169 RBU_TargetGearReq_VMC_1 7 "Invalid" 6 "Not_Used" 5 "Not_Used" 4 "Not_Used" 3 "Not_Used" 2 "Not_Used" 1 "Target_gear_P" 0 "No_Request" ;
VAL_ 169 RBU_TargetGearReqEnable_VMC_1 1 "Enable" 0 "Not enable" ;
VAL_ 169 RBU_VehicleStandstillSt 1 "The_vehicle_is_in_standstill." 0 "The_vehicle_is_not__in_standstill." ;
VAL_ 169 RBU_BrakeLightCtrlCmd 1 "Illuminate" 0 "Not_illuminate" ;
VAL_ 188 RearWheelAngle_QF 3 "Valid" 2 "Inaccurate" 1 "Initial" 0 "Invalid" ;
VAL_ 188 WorkingSt_RWS 7 "Diagnosis" 6 "Inactive" 5 "Ramping" 4 "Yellow" 3 "Red" 2 "Normal" 1 "Pending" 0 "Initialisation" ;
VAL_ 188 ErrorSt_RWS 3 "Reserved" 2 "Critical Error" 1 "General Error" 0 "No Error" ;
VAL_ 222 PbcOutActuatorState_S 7 "HapPrepared" 6 "Unknown" 5 "CompletelyReleased" 4 "Releasing" 3 "Applying" 2 "Released" 1 "HoldApplied" 0 "ParkApplied" ;
VAL_ 222 PbcOutPadAdjustmentRequest_S 1 "Request" 0 "No_Request" ;
VAL_ 222 PbcInHostAvailability_S 3 "ApplyAndRelease" 2 "Release" 1 "Apply" 0 "None" ;
VAL_ 222 PbcInApplyReleaseRequest_S 15 "Not_Used_15" 14 "Not_Used_14" 13 "Not_Used_13" 12 "Not_Used_12" 11 "Not_Used_11" 10 "Not_Used_10" 9 "Not_Used_9" 8 "HapPreparation" 7 "EmergencyParkApply" 6 "PadAdjustment" 5 "RollerbenchApply" 4 "DynamicApply" 3 "Release" 2 "HoldApply" 1 "ParkApply" 0 "None" ;
VAL_ 222 PbcInRollerbenchActive_S 1 "Inactive" 0 "Active" ;
VAL_ 222 PbcInDriveAwayIntentionIndi_0000 1 "Indicated" 0 "Not Indicated" ;
VAL_ 222 PbcEnableLineLock_S 1 "True" 0 "False" ;
VAL_ 222 PbcEnableLineRelease_S 1 "True" 0 "False" ;
VAL_ 222 EpbDegradedMode_S 7 "Not_Used_7" 6 "Not_Used_6" 5 "Not_Used_5" 4 "DegrationModeE" 3 "DegrationModeD" 2 "DegrationModeC" 1 "DegrationModeB" 0 "DegrationModeA" ;
VAL_ 222 PbcDynApplyControlState_S 15 "Not_Used_15" 14 "Not_Used_14" 13 "Not_Used_13" 12 "Not_Used_12" 11 "Not_Used_11" 10 "Not_Used_10" 9 "ePbcDynAppCntrlStErr" 8 "ePbcDynAppCntrlStStpApp" 7 "ePbcDynAppCntrlStRestrtEn" 6 "ePbcDynAppCntrlStRestrt" 5 "ePbcDynAppCntrlStHld" 4 "ePbcDynAppCntrlStIdl" 3 "ePbcDynAppCntrlStRsh" 2 "ePbcDynAppCntrlStChgDirctn" 1 "ePbcDynAppCntrlStStrt" 0 "ePbcDynAppCntrlStInactv" ;
VAL_ 222 PbcRollerbenchApplyControlS_0000 15 "Not_Used_15" 14 "Not_Used_14" 13 "ePbcRBAppCntrlStExit" 12 "ePbcRBAppCntrlStLoad" 11 "ePbcRBAppCntrlStRsh2" 10 "ePbcRBAppCntrlStMtrStkChk" 9 "ePbcRBAppCntrlStErr" 8 "ePbcRBAppCntrlStStpApp" 7 "ePbcRBAppCntrlStRestrtEn" 6 "ePbcRBAppCntrlStRestrt" 5 "ePbcRBAppCntrlStHld" 4 "ePbcRBAppCntrlStIdl" 3 "ePbcRBAppCntrlStRsh" 2 "ePbcRBAppCntrlStChgDirctn" 1 "ePbcRBAppCntrlStStrt" 0 "ePbcRBAppCntrlStInactv" ;
VAL_ 222 IsRelTchPt_S 1 "True" 0 "False" ;
VAL_ 222 IsRWAAppEn_S 1 "True" 0 "False" ;
VAL_ 222 IsRWARelEn_S 1 "True" 0 "False" ;
VAL_ 222 PbcRWAControlState_S 15 "ePbcRWACntrlStMtrStkChk" 14 "ePbcRWACntrlStErr" 13 "ePbcRWACntrlStRelDsbl" 12 "ePbcRWACntrlStRelHld" 11 "ePbcRWACntrlStAppHld" 10 "ePbcRWACntrlStStpRel" 9 "ePbcRWACntrlStRelDly" 8 "ePbcRWACntrlStStpApp" 7 "ePbcRBAppCntrlStRestrtEn" 6 "ePbcRWACntrlStResync" 5 "ePbcRWACntrlStHldInit" 4 "ePbcRWACntrlStIdl" 3 "ePbcRWACntrlStRsh" 2 "ePbcRWACntrlStChgDirctn" 1 "ePbcRWACntrlStStrt" 0 "ePbcRWACntrlStInactv" ;
